[part 2 of 2: package /MICROSAR/Dcm_swc/ComponentTypes]
AUTOSAR XML (schema 4-3-0)
package /MICROSAR/Dcm_swc/ComponentTypes
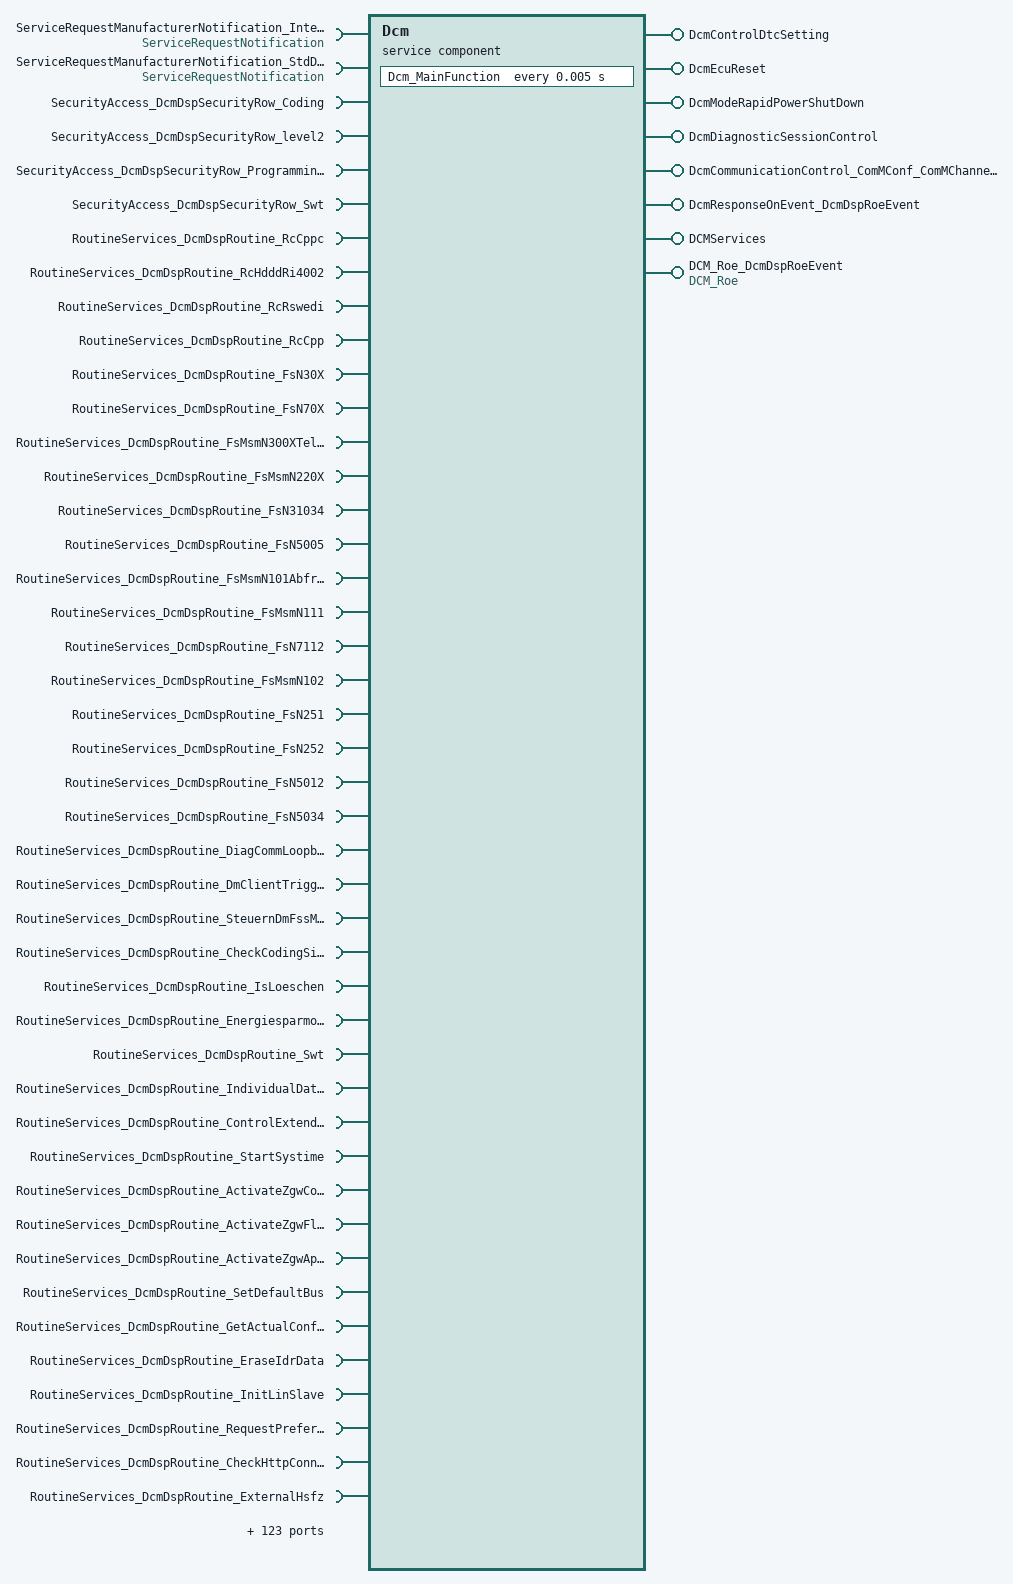
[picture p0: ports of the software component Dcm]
  service sw component type Dcm: category=SERVICE_COMPONENT
    8 x provide port:
      DcmControlDtcSetting: provided-interface=DcmControlDtcSetting
      DcmEcuReset: mode-switch-sender-com-spec{mode-group=DcmEcuReset, mode-switched-ack=timeout=0}, provided-interface=DcmEcuReset
      DcmModeRapidPowerShutDown: mode-switch-sender-com-spec{mode-group=DcmModeRapidPowerShutDown, mode-switched-ack=timeout=0}, provided-interface=DcmModeRapidPowerShutDown
      DcmDiagnosticSessionControl: provided-interface=DcmDiagnosticSessionControl
      DcmCommunicationControl_ComMConf_ComMChannel_A_FlexRay_5b5a9ac2: provided-interface=DcmCommunicationControl_ComMConf_ComMChannel_A_FlexRay_5b5a9ac2
      DcmResponseOnEvent_DcmDspRoeEvent: provided-interface=DcmResponseOnEvent_DcmDspRoeEvent
      DCMServices: provided-interface=DCMServices
      DCM_Roe_DcmDspRoeEvent: provided-interface=DCM_Roe
    169 x require port:
      ServiceRequestManufacturerNotification_IntegrationSample: required-interface=ServiceRequestNotification
      ServiceRequestManufacturerNotification_StdDiag: required-interface=ServiceRequestNotification
      SecurityAccess_DcmDspSecurityRow_Coding: required-interface=SecurityAccess_DcmDspSecurityRow_Coding
      SecurityAccess_DcmDspSecurityRow_level2: required-interface=SecurityAccess_DcmDspSecurityRow_level2
      SecurityAccess_DcmDspSecurityRow_Programming_HDD: required-interface=SecurityAccess_DcmDspSecurityRow_Programming_HDD
      SecurityAccess_DcmDspSecurityRow_Swt: required-interface=SecurityAccess_DcmDspSecurityRow_Swt
      RoutineServices_DcmDspRoutine_RcCppc: required-interface=RoutineServices_DcmDspRoutine_RcCppc
      RoutineServices_DcmDspRoutine_RcHdddRi4002: required-interface=RoutineServices_DcmDspRoutine_RcHdddRi4002
      RoutineServices_DcmDspRoutine_RcRswedi: required-interface=RoutineServices_DcmDspRoutine_RcRswedi
      RoutineServices_DcmDspRoutine_RcCpp: required-interface=RoutineServices_DcmDspRoutine_RcCpp
      RoutineServices_DcmDspRoutine_FsN30X: required-interface=RoutineServices_DcmDspRoutine_FsN30X
      RoutineServices_DcmDspRoutine_FsN70X: required-interface=RoutineServices_DcmDspRoutine_FsN70X
      RoutineServices_DcmDspRoutine_FsMsmN300XTeleservice: required-interface=RoutineServices_DcmDspRoutine_FsMsmN300XTeleservice
      RoutineServices_DcmDspRoutine_FsMsmN220X: required-interface=RoutineServices_DcmDspRoutine_FsMsmN220X
      RoutineServices_DcmDspRoutine_FsN31034: required-interface=RoutineServices_DcmDspRoutine_FsN31034
      RoutineServices_DcmDspRoutine_FsN5005: required-interface=RoutineServices_DcmDspRoutine_FsN5005
      RoutineServices_DcmDspRoutine_FsMsmN101AbfrageFzgsec: required-interface=RoutineServices_DcmDspRoutine_FsMsmN101AbfrageFzgsec
      RoutineServices_DcmDspRoutine_FsMsmN111: required-interface=RoutineServices_DcmDspRoutine_FsMsmN111
      RoutineServices_DcmDspRoutine_FsN7112: required-interface=RoutineServices_DcmDspRoutine_FsN7112
      RoutineServices_DcmDspRoutine_FsMsmN102: required-interface=RoutineServices_DcmDspRoutine_FsMsmN102
      RoutineServices_DcmDspRoutine_FsN251: required-interface=RoutineServices_DcmDspRoutine_FsN251
      RoutineServices_DcmDspRoutine_FsN252: required-interface=RoutineServices_DcmDspRoutine_FsN252
      RoutineServices_DcmDspRoutine_FsN5012: required-interface=RoutineServices_DcmDspRoutine_FsN5012
      RoutineServices_DcmDspRoutine_FsN5034: required-interface=RoutineServices_DcmDspRoutine_FsN5034
      RoutineServices_DcmDspRoutine_DiagCommLoopback: required-interface=RoutineServices_DcmDspRoutine_DiagCommLoopback
      RoutineServices_DcmDspRoutine_DmClientTriggerDtcEntry: required-interface=RoutineServices_DcmDspRoutine_DmClientTriggerDtcEntry
      RoutineServices_DcmDspRoutine_SteuernDmFssMaster: required-interface=RoutineServices_DcmDspRoutine_SteuernDmFssMaster
      RoutineServices_DcmDspRoutine_CheckCodingSignature: required-interface=RoutineServices_DcmDspRoutine_CheckCodingSignature
      RoutineServices_DcmDspRoutine_IsLoeschen: required-interface=RoutineServices_DcmDspRoutine_IsLoeschen
      RoutineServices_DcmDspRoutine_Energiesparmode: required-interface=RoutineServices_DcmDspRoutine_Energiesparmode
      RoutineServices_DcmDspRoutine_Swt: required-interface=RoutineServices_DcmDspRoutine_Swt
      RoutineServices_DcmDspRoutine_IndividualDatenRettung: required-interface=RoutineServices_DcmDspRoutine_IndividualDatenRettung
      RoutineServices_DcmDspRoutine_ControlExtendedEnergySavingState: required-interface=RoutineServices_DcmDspRoutine_ControlExtendedEnergySavingState
      RoutineServices_DcmDspRoutine_StartSystime: required-interface=RoutineServices_DcmDspRoutine_StartSystime
      RoutineServices_DcmDspRoutine_ActivateZgwCodingmode: required-interface=RoutineServices_DcmDspRoutine_ActivateZgwCodingmode
      RoutineServices_DcmDspRoutine_ActivateZgwFlashmode: required-interface=RoutineServices_DcmDspRoutine_ActivateZgwFlashmode
      RoutineServices_DcmDspRoutine_ActivateZgwApplicationmode: required-interface=RoutineServices_DcmDspRoutine_ActivateZgwApplicationmode
      RoutineServices_DcmDspRoutine_SetDefaultBus: required-interface=RoutineServices_DcmDspRoutine_SetDefaultBus
      RoutineServices_DcmDspRoutine_GetActualConfig: required-interface=RoutineServices_DcmDspRoutine_GetActualConfig
      RoutineServices_DcmDspRoutine_EraseIdrData: required-interface=RoutineServices_DcmDspRoutine_EraseIdrData
      RoutineServices_DcmDspRoutine_InitLinSlave: required-interface=RoutineServices_DcmDspRoutine_InitLinSlave
      RoutineServices_DcmDspRoutine_RequestPreferredProtocol: required-interface=RoutineServices_DcmDspRoutine_RequestPreferredProtocol
      RoutineServices_DcmDspRoutine_CheckHttpConnection: required-interface=RoutineServices_DcmDspRoutine_CheckHttpConnection
      RoutineServices_DcmDspRoutine_ExternalHsfz: required-interface=RoutineServices_DcmDspRoutine_ExternalHsfz
      RoutineServices_DcmDspRoutine_ResetAktivierungsleitung: required-interface=RoutineServices_DcmDspRoutine_ResetAktivierungsleitung
      RoutineServices_DcmDspRoutine_EthReadPhyRegister: required-interface=RoutineServices_DcmDspRoutine_EthReadPhyRegister
      RoutineServices_DcmDspRoutine_EthArlTable: required-interface=RoutineServices_DcmDspRoutine_EthArlTable
      RoutineServices_DcmDspRoutine_EthArpTable: required-interface=RoutineServices_DcmDspRoutine_EthArpTable
      RoutineServices_DcmDspRoutine_EthPhySwitchEngineReset: required-interface=RoutineServices_DcmDspRoutine_EthPhySwitchEngineReset
      RoutineServices_DcmDspRoutine_EthIpConfiguration: required-interface=RoutineServices_DcmDspRoutine_EthIpConfiguration
      RoutineServices_DcmDspRoutine_EthPhyIdentifier: required-interface=RoutineServices_DcmDspRoutine_EthPhyIdentifier
      RoutineServices_DcmDspRoutine_EthGetPortTxRxStats: required-interface=RoutineServices_DcmDspRoutine_EthGetPortTxRxStats
      RoutineServices_DcmDspRoutine_EthResetPortTxRxStats: required-interface=RoutineServices_DcmDspRoutine_EthResetPortTxRxStats
      RoutineServices_DcmDspRoutine_EthEnableTestMode: required-interface=RoutineServices_DcmDspRoutine_EthEnableTestMode
      RoutineServices_DcmDspRoutine_EthWritePhyRegister: required-interface=RoutineServices_DcmDspRoutine_EthWritePhyRegister
      RoutineServices_DcmDspRoutine_EthExtendedArlTable: required-interface=RoutineServices_DcmDspRoutine_EthExtendedArlTable
      RoutineServices_DcmDspRoutine_EthGetDhcpStatus: required-interface=RoutineServices_DcmDspRoutine_EthGetDhcpStatus
      RoutineServices_DcmDspRoutine_EthGetEthernetSwitches: required-interface=RoutineServices_DcmDspRoutine_EthGetEthernetSwitches
      RoutineServices_DcmDspRoutine_EthGetSwitchVlanConfiguration: required-interface=RoutineServices_DcmDspRoutine_EthGetSwitchVlanConfiguration
      RoutineServices_DcmDspRoutine_FehlerspeicherEndeWerksablauf: required-interface=RoutineServices_DcmDspRoutine_FehlerspeicherEndeWerksablauf
      RoutineServices_DcmDspRoutine_AblageSystemkontext: required-interface=RoutineServices_DcmDspRoutine_AblageSystemkontext
      RoutineServices_DcmDspRoutine_InitLinBus: required-interface=RoutineServices_DcmDspRoutine_InitLinBus
      RoutineServices_DcmDspRoutine_RamDatenSchreiben: required-interface=RoutineServices_DcmDspRoutine_RamDatenSchreiben
      RoutineServices_DcmDspRoutine_RcPad: required-interface=RoutineServices_DcmDspRoutine_RcPad
      DataServices_DcmDspData_SvkBackup39: required-interface=DataServices_DcmDspData_SvkBackup39
      DataServices_DcmDspData_SvkBackup38: required-interface=DataServices_DcmDspData_SvkBackup38
      DataServices_DcmDspData_SvkBackup37: required-interface=DataServices_DcmDspData_SvkBackup37
      DataServices_DcmDspData_SvkBackup36: required-interface=DataServices_DcmDspData_SvkBackup36
      DataServices_DcmDspData_SvkBackup35: required-interface=DataServices_DcmDspData_SvkBackup35
      DataServices_DcmDspData_SvkBackup34: required-interface=DataServices_DcmDspData_SvkBackup34
      DataServices_DcmDspData_SvkBackup33: required-interface=DataServices_DcmDspData_SvkBackup33
      DataServices_DcmDspData_SvkBackup32: required-interface=DataServices_DcmDspData_SvkBackup32
      DataServices_DcmDspData_SvkBackup31: required-interface=DataServices_DcmDspData_SvkBackup31
      DataServices_DcmDspData_SvkBackup30: required-interface=DataServices_DcmDspData_SvkBackup30
      DataServices_DcmDspData_EthGetNumberOfPorts: required-interface=DataServices_DcmDspData_EthGetNumberOfPorts
      DataServices_DcmDspData_SvkBackup28: required-interface=DataServices_DcmDspData_SvkBackup28
      DataServices_DcmDspData_SvkBackup27: required-interface=DataServices_DcmDspData_SvkBackup27
      DataServices_DcmDspData_SvkBackup26: required-interface=DataServices_DcmDspData_SvkBackup26
      DataServices_DcmDspData_SvkBackup25: required-interface=DataServices_DcmDspData_SvkBackup25
      DataServices_DcmDspData_SvkBackup24: required-interface=DataServices_DcmDspData_SvkBackup24
      DataServices_DcmDspData_SvkBackup23: required-interface=DataServices_DcmDspData_SvkBackup23
      DataServices_DcmDspData_SvkBackup22: required-interface=DataServices_DcmDspData_SvkBackup22
      DataServices_DcmDspData_SvkBackup21: required-interface=DataServices_DcmDspData_SvkBackup21
      DataServices_DcmDspData_SvkBackup20: required-interface=DataServices_DcmDspData_SvkBackup20
      DataServices_DcmDspData_SvkBackup29: required-interface=DataServices_DcmDspData_SvkBackup29
      DataServices_DcmDspData_ListManipulationSecurityArtifact: required-interface=DataServices_DcmDspData_ListManipulationSecurityArtifact
      DataServices_DcmDspData_SvkBackup17: required-interface=DataServices_DcmDspData_SvkBackup17
      DataServices_DcmDspData_SvkBackup16: required-interface=DataServices_DcmDspData_SvkBackup16
      DataServices_DcmDspData_SvkBackup15: required-interface=DataServices_DcmDspData_SvkBackup15
      DataServices_DcmDspData_SvkBackup14: required-interface=DataServices_DcmDspData_SvkBackup14
      DataServices_DcmDspData_SvkBackup13: required-interface=DataServices_DcmDspData_SvkBackup13
      DataServices_DcmDspData_SvkBackup12: required-interface=DataServices_DcmDspData_SvkBackup12
      DataServices_DcmDspData_SvkBackup11: required-interface=DataServices_DcmDspData_SvkBackup11
      DataServices_DcmDspData_SvkBackup10: required-interface=DataServices_DcmDspData_SvkBackup10
      DataServices_DcmDspData_SvkBackup19: required-interface=DataServices_DcmDspData_SvkBackup19
      DataServices_DcmDspData_SvkBackup18: required-interface=DataServices_DcmDspData_SvkBackup18
      DataServices_DcmDspData_SvkBackup06: required-interface=DataServices_DcmDspData_SvkBackup06
      DataServices_DcmDspData_SvkBackup05: required-interface=DataServices_DcmDspData_SvkBackup05
      DataServices_DcmDspData_SvkBackup04: required-interface=DataServices_DcmDspData_SvkBackup04
      DataServices_DcmDspData_SvkBackup03: required-interface=DataServices_DcmDspData_SvkBackup03
      DataServices_DcmDspData_SvkBackup02: required-interface=DataServices_DcmDspData_SvkBackup02
      DataServices_DcmDspData_SvkBackup01: required-interface=DataServices_DcmDspData_SvkBackup01
      DataServices_DcmDspData_StatusSystime: required-interface=DataServices_DcmDspData_StatusSystime
      DataServices_DcmDspData_SvkBackup09: required-interface=DataServices_DcmDspData_SvkBackup09
      DataServices_DcmDspData_SvkBackup08: required-interface=DataServices_DcmDspData_SvkBackup08
      DataServices_DcmDspData_SvkBackup07: required-interface=DataServices_DcmDspData_SvkBackup07
      DataServices_DcmDspData_HddDownloadTimeToCompletion: required-interface=DataServices_DcmDspData_HddDownloadTimeToCompletion
      DataServices_DcmDspData_StatusDmFssMaster: required-interface=DataServices_DcmDspData_StatusDmFssMaster
      DataServices_DcmDspData_HddDownloadStatus: required-interface=DataServices_DcmDspData_HddDownloadStatus
      DataServices_DcmDspData_SvkAktuell: required-interface=DataServices_DcmDspData_SvkAktuell
      DataServices_DcmDspData_Readhwmodificationindex: required-interface=DataServices_DcmDspData_Readhwmodificationindex
      DataServices_DcmDspData_SensorenAnzahlLesen: required-interface=DataServices_DcmDspData_SensorenAnzahlLesen
      DataServices_DcmDspData_IndivDataTable: required-interface=DataServices_DcmDspData_IndivDataTable
      DataServices_DcmDspData_DmDtcAktiveMeldung: required-interface=DataServices_DcmDspData_DmDtcAktiveMeldung
      DataServices_DcmDspData_SwfkDeleteSupported: required-interface=DataServices_DcmDspData_SwfkDeleteSupported
      DataServices_DcmDspData_FlashTimingParameter: required-interface=DataServices_DcmDspData_FlashTimingParameter
      DataServices_DcmDspData_ListManipulationApplicationData: required-interface=DataServices_DcmDspData_ListManipulationApplicationData
      DataServices_DcmDspData_Vin: required-interface=DataServices_DcmDspData_Vin
      DataServices_DcmDspData_EnergySavingState: required-interface=DataServices_DcmDspData_EnergySavingState
      DataServices_DcmDspData_ReadActiveSessionState: required-interface=DataServices_DcmDspData_ReadActiveSessionState
      DataServices_DcmDspData_EthPhyLinkState: required-interface=DataServices_DcmDspData_EthPhyLinkState
      DataServices_DcmDspData_EthSignalQuality: required-interface=DataServices_DcmDspData_EthSignalQuality
      DataServices_DcmDspData_ListManipulationSw: required-interface=DataServices_DcmDspData_ListManipulationSw
      DataServices_DcmDspData_Herstelldatum: required-interface=DataServices_DcmDspData_Herstelldatum
      DataServices_DcmDspData_Sekundaererfehlerspeicher: required-interface=DataServices_DcmDspData_Sekundaererfehlerspeicher
      DataServices_DcmDspData_SystemSupplierIdentifier: required-interface=DataServices_DcmDspData_SystemSupplierIdentifier
      DataServices_DcmDspData_MileKmEeprom: required-interface=DataServices_DcmDspData_MileKmEeprom
      DataServices_DcmDspData_ListManipulationGeneral: required-interface=DataServices_DcmDspData_ListManipulationGeneral
      DataServices_DcmDspData_SvkWerk: required-interface=DataServices_DcmDspData_SvkWerk
      DataServices_DcmDspData_ProgrammingCounterMaxValue: required-interface=DataServices_DcmDspData_ProgrammingCounterMaxValue
      DataServices_DcmDspData_EcuSerialNumber: required-interface=DataServices_DcmDspData_EcuSerialNumber
      DataServices_DcmDspData_SgbdIdx: required-interface=DataServices_DcmDspData_SgbdIdx
      DataServices_DcmDspData_ZgwZertifikat: required-interface=DataServices_DcmDspData_ZgwZertifikat
      DataServices_DcmDspData_ListManipulationSecureBoot: required-interface=DataServices_DcmDspData_ListManipulationSecureBoot
      DataServices_DcmDspData_DmIsDtcActiveResponse: required-interface=DataServices_DcmDspData_DmIsDtcActiveResponse
      DataServices_DcmDspData_ExtendedEnergySavingState: required-interface=DataServices_DcmDspData_ExtendedEnergySavingState
      DataServices_DcmDspData_SvkBackup61: required-interface=DataServices_DcmDspData_SvkBackup61
      DataServices_DcmDspData_PiaProfile0: required-interface=DataServices_DcmDspData_PiaProfile0
      DataServices_DcmDspData_SvkBackup60: required-interface=DataServices_DcmDspData_SvkBackup60
      DataServices_DcmDspData_PiaProfile1: required-interface=DataServices_DcmDspData_PiaProfile1
      DataServices_DcmDspData_PiaProfile2: required-interface=DataServices_DcmDspData_PiaProfile2
      DataServices_DcmDspData_SvkSysSupplier: required-interface=DataServices_DcmDspData_SvkSysSupplier
      DataServices_DcmDspData_PiaProfileA: required-interface=DataServices_DcmDspData_PiaProfileA
      DataServices_DcmDspData_SvkBackup59: required-interface=DataServices_DcmDspData_SvkBackup59
      DataServices_DcmDspData_SvkBackup58: required-interface=DataServices_DcmDspData_SvkBackup58
      DataServices_DcmDspData_SvkBackup57: required-interface=DataServices_DcmDspData_SvkBackup57
      DataServices_DcmDspData_SvkBackup56: required-interface=DataServices_DcmDspData_SvkBackup56
      DataServices_DcmDspData_SvkBackup55: required-interface=DataServices_DcmDspData_SvkBackup55
      DataServices_DcmDspData_SvkBackup54: required-interface=DataServices_DcmDspData_SvkBackup54
      DataServices_DcmDspData_SvkBackup53: required-interface=DataServices_DcmDspData_SvkBackup53
      DataServices_DcmDspData_SvkBackup52: required-interface=DataServices_DcmDspData_SvkBackup52
      DataServices_DcmDspData_SvkBackup51: required-interface=DataServices_DcmDspData_SvkBackup51
      DataServices_DcmDspData_SvkBackup50: required-interface=DataServices_DcmDspData_SvkBackup50
      DataServices_DcmDspData_ProgrammingCounter: required-interface=DataServices_DcmDspData_ProgrammingCounter
      DataServices_DcmDspData_Systemzeit: required-interface=DataServices_DcmDspData_Systemzeit
      DataServices_DcmDspData_SvkBackup49: required-interface=DataServices_DcmDspData_SvkBackup49
      DataServices_DcmDspData_SvkBackup48: required-interface=DataServices_DcmDspData_SvkBackup48
      DataServices_DcmDspData_SvkBackup47: required-interface=DataServices_DcmDspData_SvkBackup47
      DataServices_DcmDspData_SvkBackup46: required-interface=DataServices_DcmDspData_SvkBackup46
      DataServices_DcmDspData_SvkBackup45: required-interface=DataServices_DcmDspData_SvkBackup45
      DataServices_DcmDspData_SvkBackup44: required-interface=DataServices_DcmDspData_SvkBackup44
      DataServices_DcmDspData_SvkBackup43: required-interface=DataServices_DcmDspData_SvkBackup43
      DataServices_DcmDspData_SvkBackup42: required-interface=DataServices_DcmDspData_SvkBackup42
      DataServices_DcmDspData_SvkBackup41: required-interface=DataServices_DcmDspData_SvkBackup41
      DataServices_DcmDspData_SvkBackup40: required-interface=DataServices_DcmDspData_SvkBackup40
      DataServices_DIDRange_DcmDspDidRange_Coding: required-interface=DataServices_DIDRange_DcmDspDidRange_Coding
      DataServices_Data_DcmDspDid_SensorLesen_{1..3}: required-interface=DataServices_Data_DcmDspDid_SensorLesen_{1..3}
    behavior DcmInternalBehavior:
      data-type-mapping=DcmMappingSet
      handle-termination-and-restart=NO-SUPPORT
      included-data-type-set=data-type=[Dcm_ConfirmationStatusType, Dcm_OpStatusType, Dcm_DidSupportedType, Dcm_NegativeResponseCodeType, Dcm_ProtocolType, Dcm_RequestKindType, Dcm_SecLevelType, Dcm_SesCtrlType, Dcm_ControlDtcSettingType, Dcm_EcuResetType, Dcm_ModeRapidPowerShutDownType, Dcm_DiagnosticSessionControlType, Dcm_CommunicationModeType, Dcm_ResponseOnEventType]
      timing event Timer_Dcm_MainFunction: start-on-event=Dcm_MainFunction, period=0.005
      7 x operation invoked event:
        OpEventGetActiveProtocol_GetActiveProtocol_DCMServices: start-on-event=GetActiveProtocol, operation=DCMServices.GetActiveProtocol
        OpEventGetSesCtrlType_GetSesCtrlType_DCMServices: start-on-event=GetSesCtrlType, operation=DCMServices.GetSesCtrlType
        OpEventResetToDefaultSession_ResetToDefaultSession_DCMServices: start-on-event=ResetToDefaultSession, operation=DCMServices.ResetToDefaultSession
        OpEventGetSecurityLevel_GetSecurityLevel_DCMServices: start-on-event=GetSecurityLevel, operation=DCMServices.GetSecurityLevel
        OpEventSetActiveDiagnostic_SetActiveDiagnostic_DCMServices: start-on-event=SetActiveDiagnostic, operation=DCMServices.SetActiveDiagnostic
        OpEventGetRequestKind_GetRequestKind_DCMServices: start-on-event=GetRequestKind, operation=DCMServices.GetRequestKind
        OpEventTriggerOnEvent_TriggerOnEvent_DCM_Roe_DcmDspRoeEvent: start-on-event=TriggerOnEvent, operation=DCM_Roe_DcmDspRoeEvent.TriggerOnEvent
      port-api-options:
        enable-take-address=true, indirect-api=false, port=DcmControlDtcSetting
        enable-take-address=true, indirect-api=false, port=DcmEcuReset
        enable-take-address=true, indirect-api=false, port=DcmModeRapidPowerShutDown
        enable-take-address=true, indirect-api=false, port=DcmDiagnosticSessionControl
        enable-take-address=true, indirect-api=false, port=DcmCommunicationControl_ComMConf_ComMChannel_A_FlexRay_5b5a9ac2
        enable-take-address=true, indirect-api=false, port=DcmResponseOnEvent_DcmDspRoeEvent
        enable-take-address=true, indirect-api=false, port=DCMServices
        {enable-take-address=true, indirect-api=false, port-defined-argument-value{value=0, value-type=uint8}, port=DCM_Roe_DcmDspRoeEvent}
        enable-take-address=true, indirect-api=false, port=ServiceRequestManufacturerNotification_IntegrationSample
        enable-take-address=true, indirect-api=false, port=ServiceRequestManufacturerNotification_StdDiag
        enable-take-address=true, indirect-api=false, port=SecurityAccess_DcmDspSecurityRow_Coding
        enable-take-address=true, indirect-api=false, port=SecurityAccess_DcmDspSecurityRow_level2
        enable-take-address=true, indirect-api=false, port=SecurityAccess_DcmDspSecurityRow_Programming_HDD
        enable-take-address=true, indirect-api=false, port=SecurityAccess_DcmDspSecurityRow_Swt
        enable-take-address=true, indirect-api=false, port=RoutineServices_DcmDspRoutine_RcCppc
        enable-take-address=true, indirect-api=false, port=RoutineServices_DcmDspRoutine_RcHdddRi4002
        enable-take-address=true, indirect-api=false, port=RoutineServices_DcmDspRoutine_RcRswedi
        enable-take-address=true, indirect-api=false, port=RoutineServices_DcmDspRoutine_RcCpp
        enable-take-address=true, indirect-api=false, port=RoutineServices_DcmDspRoutine_FsN30X
        enable-take-address=true, indirect-api=false, port=RoutineServices_DcmDspRoutine_FsN70X
        enable-take-address=true, indirect-api=false, port=RoutineServices_DcmDspRoutine_FsMsmN300XTeleservice
        enable-take-address=true, indirect-api=false, port=RoutineServices_DcmDspRoutine_FsMsmN220X
        enable-take-address=true, indirect-api=false, port=RoutineServices_DcmDspRoutine_FsN31034
        enable-take-address=true, indirect-api=false, port=RoutineServices_DcmDspRoutine_FsN5005
        enable-take-address=true, indirect-api=false, port=RoutineServices_DcmDspRoutine_FsMsmN101AbfrageFzgsec
        enable-take-address=true, indirect-api=false, port=RoutineServices_DcmDspRoutine_FsMsmN111
        enable-take-address=true, indirect-api=false, port=RoutineServices_DcmDspRoutine_FsN7112
        enable-take-address=true, indirect-api=false, port=RoutineServices_DcmDspRoutine_FsMsmN102
        enable-take-address=true, indirect-api=false, port=RoutineServices_DcmDspRoutine_FsN251
        enable-take-address=true, indirect-api=false, port=RoutineServices_DcmDspRoutine_FsN252
        enable-take-address=true, indirect-api=false, port=RoutineServices_DcmDspRoutine_FsN5012
        enable-take-address=true, indirect-api=false, port=RoutineServices_DcmDspRoutine_FsN5034
        enable-take-address=true, indirect-api=false, port=RoutineServices_DcmDspRoutine_DiagCommLoopback
        enable-take-address=true, indirect-api=false, port=RoutineServices_DcmDspRoutine_DmClientTriggerDtcEntry
        enable-take-address=true, indirect-api=false, port=RoutineServices_DcmDspRoutine_SteuernDmFssMaster
        enable-take-address=true, indirect-api=false, port=RoutineServices_DcmDspRoutine_CheckCodingSignature
        enable-take-address=true, indirect-api=false, port=RoutineServices_DcmDspRoutine_IsLoeschen
        enable-take-address=true, indirect-api=false, port=RoutineServices_DcmDspRoutine_Energiesparmode
        enable-take-address=true, indirect-api=false, port=RoutineServices_DcmDspRoutine_Swt
        enable-take-address=true, indirect-api=false, port=RoutineServices_DcmDspRoutine_IndividualDatenRettung
        enable-take-address=true, indirect-api=false, port=RoutineServices_DcmDspRoutine_ControlExtendedEnergySavingState
        enable-take-address=true, indirect-api=false, port=RoutineServices_DcmDspRoutine_StartSystime
        enable-take-address=true, indirect-api=false, port=RoutineServices_DcmDspRoutine_ActivateZgwCodingmode
        enable-take-address=true, indirect-api=false, port=RoutineServices_DcmDspRoutine_ActivateZgwFlashmode
        enable-take-address=true, indirect-api=false, port=RoutineServices_DcmDspRoutine_ActivateZgwApplicationmode
        enable-take-address=true, indirect-api=false, port=RoutineServices_DcmDspRoutine_SetDefaultBus
        enable-take-address=true, indirect-api=false, port=RoutineServices_DcmDspRoutine_GetActualConfig
        enable-take-address=true, indirect-api=false, port=RoutineServices_DcmDspRoutine_EraseIdrData
        enable-take-address=true, indirect-api=false, port=RoutineServices_DcmDspRoutine_InitLinSlave
        enable-take-address=true, indirect-api=false, port=RoutineServices_DcmDspRoutine_RequestPreferredProtocol
        enable-take-address=true, indirect-api=false, port=RoutineServices_DcmDspRoutine_CheckHttpConnection
        enable-take-address=true, indirect-api=false, port=RoutineServices_DcmDspRoutine_ExternalHsfz
        enable-take-address=true, indirect-api=false, port=RoutineServices_DcmDspRoutine_ResetAktivierungsleitung
        enable-take-address=true, indirect-api=false, port=RoutineServices_DcmDspRoutine_EthReadPhyRegister
        enable-take-address=true, indirect-api=false, port=RoutineServices_DcmDspRoutine_EthArlTable
        enable-take-address=true, indirect-api=false, port=RoutineServices_DcmDspRoutine_EthArpTable
        enable-take-address=true, indirect-api=false, port=RoutineServices_DcmDspRoutine_EthPhySwitchEngineReset
        enable-take-address=true, indirect-api=false, port=RoutineServices_DcmDspRoutine_EthIpConfiguration
        enable-take-address=true, indirect-api=false, port=RoutineServices_DcmDspRoutine_EthPhyIdentifier
        enable-take-address=true, indirect-api=false, port=RoutineServices_DcmDspRoutine_EthGetPortTxRxStats
        enable-take-address=true, indirect-api=false, port=RoutineServices_DcmDspRoutine_EthResetPortTxRxStats
        enable-take-address=true, indirect-api=false, port=RoutineServices_DcmDspRoutine_EthEnableTestMode
        enable-take-address=true, indirect-api=false, port=RoutineServices_DcmDspRoutine_EthWritePhyRegister
        enable-take-address=true, indirect-api=false, port=RoutineServices_DcmDspRoutine_EthExtendedArlTable
        enable-take-address=true, indirect-api=false, port=RoutineServices_DcmDspRoutine_EthGetDhcpStatus
        enable-take-address=true, indirect-api=false, port=RoutineServices_DcmDspRoutine_EthGetEthernetSwitches
        enable-take-address=true, indirect-api=false, port=RoutineServices_DcmDspRoutine_EthGetSwitchVlanConfiguration
        enable-take-address=true, indirect-api=false, port=RoutineServices_DcmDspRoutine_FehlerspeicherEndeWerksablauf
        enable-take-address=true, indirect-api=false, port=RoutineServices_DcmDspRoutine_AblageSystemkontext
        enable-take-address=true, indirect-api=false, port=RoutineServices_DcmDspRoutine_InitLinBus
        enable-take-address=true, indirect-api=false, port=RoutineServices_DcmDspRoutine_RamDatenSchreiben
        enable-take-address=true, indirect-api=false, port=RoutineServices_DcmDspRoutine_RcPad
        enable-take-address=true, indirect-api=false, port=DataServices_DcmDspData_SvkBackup39
        enable-take-address=true, indirect-api=false, port=DataServices_DcmDspData_SvkBackup38
        enable-take-address=true, indirect-api=false, port=DataServices_DcmDspData_SvkBackup37
        enable-take-address=true, indirect-api=false, port=DataServices_DcmDspData_SvkBackup36
        enable-take-address=true, indirect-api=false, port=DataServices_DcmDspData_SvkBackup35
        enable-take-address=true, indirect-api=false, port=DataServices_DcmDspData_SvkBackup34
        enable-take-address=true, indirect-api=false, port=DataServices_DcmDspData_SvkBackup33
        enable-take-address=true, indirect-api=false, port=DataServices_DcmDspData_SvkBackup32
        enable-take-address=true, indirect-api=false, port=DataServices_DcmDspData_SvkBackup31
        enable-take-address=true, indirect-api=false, port=DataServices_DcmDspData_SvkBackup30
        enable-take-address=true, indirect-api=false, port=DataServices_DcmDspData_EthGetNumberOfPorts
        enable-take-address=true, indirect-api=false, port=DataServices_DcmDspData_SvkBackup28
        enable-take-address=true, indirect-api=false, port=DataServices_DcmDspData_SvkBackup27
        enable-take-address=true, indirect-api=false, port=DataServices_DcmDspData_SvkBackup26
        enable-take-address=true, indirect-api=false, port=DataServices_DcmDspData_SvkBackup25
        enable-take-address=true, indirect-api=false, port=DataServices_DcmDspData_SvkBackup24
        enable-take-address=true, indirect-api=false, port=DataServices_DcmDspData_SvkBackup23
        enable-take-address=true, indirect-api=false, port=DataServices_DcmDspData_SvkBackup22
        enable-take-address=true, indirect-api=false, port=DataServices_DcmDspData_SvkBackup21
        enable-take-address=true, indirect-api=false, port=DataServices_DcmDspData_SvkBackup20
        enable-take-address=true, indirect-api=false, port=DataServices_DcmDspData_SvkBackup29
        enable-take-address=true, indirect-api=false, port=DataServices_DcmDspData_ListManipulationSecurityArtifact
        enable-take-address=true, indirect-api=false, port=DataServices_DcmDspData_SvkBackup17
        enable-take-address=true, indirect-api=false, port=DataServices_DcmDspData_SvkBackup16
        enable-take-address=true, indirect-api=false, port=DataServices_DcmDspData_SvkBackup15
        enable-take-address=true, indirect-api=false, port=DataServices_DcmDspData_SvkBackup14
        enable-take-address=true, indirect-api=false, port=DataServices_DcmDspData_SvkBackup13
        enable-take-address=true, indirect-api=false, port=DataServices_DcmDspData_SvkBackup12
        enable-take-address=true, indirect-api=false, port=DataServices_DcmDspData_SvkBackup11
        enable-take-address=true, indirect-api=false, port=DataServices_DcmDspData_SvkBackup10
        enable-take-address=true, indirect-api=false, port=DataServices_DcmDspData_SvkBackup19
        enable-take-address=true, indirect-api=false, port=DataServices_DcmDspData_SvkBackup18
        enable-take-address=true, indirect-api=false, port=DataServices_DcmDspData_SvkBackup06
        enable-take-address=true, indirect-api=false, port=DataServices_DcmDspData_SvkBackup05
        enable-take-address=true, indirect-api=false, port=DataServices_DcmDspData_SvkBackup04
        enable-take-address=true, indirect-api=false, port=DataServices_DcmDspData_SvkBackup03
        enable-take-address=true, indirect-api=false, port=DataServices_DcmDspData_SvkBackup02
        enable-take-address=true, indirect-api=false, port=DataServices_DcmDspData_SvkBackup01
        enable-take-address=true, indirect-api=false, port=DataServices_DcmDspData_StatusSystime
        enable-take-address=true, indirect-api=false, port=DataServices_DcmDspData_SvkBackup09
        enable-take-address=true, indirect-api=false, port=DataServices_DcmDspData_SvkBackup08
        enable-take-address=true, indirect-api=false, port=DataServices_DcmDspData_SvkBackup07
        enable-take-address=true, indirect-api=false, port=DataServices_DcmDspData_HddDownloadTimeToCompletion
        enable-take-address=true, indirect-api=false, port=DataServices_DcmDspData_StatusDmFssMaster
        enable-take-address=true, indirect-api=false, port=DataServices_DcmDspData_HddDownloadStatus
        enable-take-address=true, indirect-api=false, port=DataServices_DcmDspData_SvkAktuell
        enable-take-address=true, indirect-api=false, port=DataServices_DcmDspData_Readhwmodificationindex
        enable-take-address=true, indirect-api=false, port=DataServices_DcmDspData_SensorenAnzahlLesen
        enable-take-address=true, indirect-api=false, port=DataServices_DcmDspData_IndivDataTable
        enable-take-address=true, indirect-api=false, port=DataServices_DcmDspData_DmDtcAktiveMeldung
        enable-take-address=true, indirect-api=false, port=DataServices_DcmDspData_SwfkDeleteSupported
        enable-take-address=true, indirect-api=false, port=DataServices_DcmDspData_FlashTimingParameter
        enable-take-address=true, indirect-api=false, port=DataServices_DcmDspData_ListManipulationApplicationData
        enable-take-address=true, indirect-api=false, port=DataServices_DcmDspData_Vin
        enable-take-address=true, indirect-api=false, port=DataServices_DcmDspData_EnergySavingState
        enable-take-address=true, indirect-api=false, port=DataServices_DcmDspData_ReadActiveSessionState
        enable-take-address=true, indirect-api=false, port=DataServices_DcmDspData_EthPhyLinkState
        enable-take-address=true, indirect-api=false, port=DataServices_DcmDspData_EthSignalQuality
        enable-take-address=true, indirect-api=false, port=DataServices_DcmDspData_ListManipulationSw
        enable-take-address=true, indirect-api=false, port=DataServices_DcmDspData_Herstelldatum
        enable-take-address=true, indirect-api=false, port=DataServices_DcmDspData_Sekundaererfehlerspeicher
        enable-take-address=true, indirect-api=false, port=DataServices_DcmDspData_SystemSupplierIdentifier
        enable-take-address=true, indirect-api=false, port=DataServices_DcmDspData_MileKmEeprom
        enable-take-address=true, indirect-api=false, port=DataServices_DcmDspData_ListManipulationGeneral
        enable-take-address=true, indirect-api=false, port=DataServices_DcmDspData_SvkWerk
        enable-take-address=true, indirect-api=false, port=DataServices_DcmDspData_ProgrammingCounterMaxValue
        enable-take-address=true, indirect-api=false, port=DataServices_DcmDspData_EcuSerialNumber
        enable-take-address=true, indirect-api=false, port=DataServices_DcmDspData_SgbdIdx
        enable-take-address=true, indirect-api=false, port=DataServices_DcmDspData_ZgwZertifikat
        enable-take-address=true, indirect-api=false, port=DataServices_DcmDspData_ListManipulationSecureBoot
        enable-take-address=true, indirect-api=false, port=DataServices_DcmDspData_DmIsDtcActiveResponse
        enable-take-address=true, indirect-api=false, port=DataServices_DcmDspData_ExtendedEnergySavingState
        enable-take-address=true, indirect-api=false, port=DataServices_DcmDspData_SvkBackup61
        enable-take-address=true, indirect-api=false, port=DataServices_DcmDspData_PiaProfile0
        enable-take-address=true, indirect-api=false, port=DataServices_DcmDspData_SvkBackup60
        enable-take-address=true, indirect-api=false, port=DataServices_DcmDspData_PiaProfile1
        enable-take-address=true, indirect-api=false, port=DataServices_DcmDspData_PiaProfile2
        enable-take-address=true, indirect-api=false, port=DataServices_DcmDspData_SvkSysSupplier
        enable-take-address=true, indirect-api=false, port=DataServices_DcmDspData_PiaProfileA
        enable-take-address=true, indirect-api=false, port=DataServices_DcmDspData_SvkBackup59
        enable-take-address=true, indirect-api=false, port=DataServices_DcmDspData_SvkBackup58
        enable-take-address=true, indirect-api=false, port=DataServices_DcmDspData_SvkBackup57
        enable-take-address=true, indirect-api=false, port=DataServices_DcmDspData_SvkBackup56
        enable-take-address=true, indirect-api=false, port=DataServices_DcmDspData_SvkBackup55
        enable-take-address=true, indirect-api=false, port=DataServices_DcmDspData_SvkBackup54
        enable-take-address=true, indirect-api=false, port=DataServices_DcmDspData_SvkBackup53
        enable-take-address=true, indirect-api=false, port=DataServices_DcmDspData_SvkBackup52
        enable-take-address=true, indirect-api=false, port=DataServices_DcmDspData_SvkBackup51
        enable-take-address=true, indirect-api=false, port=DataServices_DcmDspData_SvkBackup50
        enable-take-address=true, indirect-api=false, port=DataServices_DcmDspData_ProgrammingCounter
        enable-take-address=true, indirect-api=false, port=DataServices_DcmDspData_Systemzeit
        enable-take-address=true, indirect-api=false, port=DataServices_DcmDspData_SvkBackup49
        enable-take-address=true, indirect-api=false, port=DataServices_DcmDspData_SvkBackup48
        enable-take-address=true, indirect-api=false, port=DataServices_DcmDspData_SvkBackup47
        enable-take-address=true, indirect-api=false, port=DataServices_DcmDspData_SvkBackup46
        enable-take-address=true, indirect-api=false, port=DataServices_DcmDspData_SvkBackup45
        enable-take-address=true, indirect-api=false, port=DataServices_DcmDspData_SvkBackup44
        enable-take-address=true, indirect-api=false, port=DataServices_DcmDspData_SvkBackup43
        enable-take-address=true, indirect-api=false, port=DataServices_DcmDspData_SvkBackup42
        enable-take-address=true, indirect-api=false, port=DataServices_DcmDspData_SvkBackup41
        enable-take-address=true, indirect-api=false, port=DataServices_DcmDspData_SvkBackup40
        enable-take-address=true, indirect-api=false, port=DataServices_DIDRange_DcmDspDidRange_Coding
        enable-take-address=true, indirect-api=false, port=DataServices_Data_DcmDspDid_SensorLesen_{1..3}
      8 x runnable:
        Dcm_MainFunction
          6 x mode switch point:
            ModeSwitchPointDcm_MainFunction_DcmControlDtcSetting_DcmControlDtcSetting: mode-group=DcmControlDtcSetting.DcmControlDtcSetting
            ModeSwitchPointDcm_MainFunction_DcmEcuReset_DcmEcuReset: mode-group=DcmEcuReset.DcmEcuReset
            ModeSwitchPointDcm_MainFunction_DcmModeRapidPowerShutDown_DcmModeRapidPowerShutDown: mode-group=DcmModeRapidPowerShutDown.DcmModeRapidPowerShutDown
            ModeSwitchPointDcm_MainFunction_DcmDiagnosticSessionControl_DcmDiagnosticSessionControl: mode-group=DcmDiagnosticSessionControl.DcmDiagnosticSessionControl
            ModeSwitchPointDcm_MainFunction_DcmCommunicationControl_ComMConf_ComMChannel_A_FlexRay_5b5a9ac2_DcmCommunicationControl_aef52ce2: mode-group=DcmCommunicationControl_ComMConf_ComMChannel_A_FlexRay_5b5a9ac2.DcmCommunicationControl_ComMConf_ComMChannel_A_FlexRay_5b5a9ac2
            ModeSwitchPointDcm_MainFunction_DcmResponseOnEvent_DcmDspRoeEvent_DcmResponseOnEvent_DcmDspRoeEvent: mode-group=DcmResponseOnEvent_DcmDspRoeEvent.DcmResponseOnEvent_DcmDspRoeEvent
          292 x sync call, all with timeout=0:
            OpServerCallDcm_MainFunction_Indication_ServiceRequestManufacturerNotification_IntegrationSample: operation=ServiceRequestManufacturerNotification_IntegrationSample.Indication
            OpServerCallDcm_MainFunction_Confirmation_ServiceRequestManufacturerNotification_IntegrationSample: operation=ServiceRequestManufacturerNotification_IntegrationSample.Confirmation
            OpServerCallDcm_MainFunction_Indication_ServiceRequestManufacturerNotification_StdDiag: operation=ServiceRequestManufacturerNotification_StdDiag.Indication
            OpServerCallDcm_MainFunction_Confirmation_ServiceRequestManufacturerNotification_StdDiag: operation=ServiceRequestManufacturerNotification_StdDiag.Confirmation
            OpServerCallDcm_MainFunction_GetSeed_SecurityAccess_DcmDspSecurityRow_Coding: operation=SecurityAccess_DcmDspSecurityRow_Coding.GetSeed
            OpServerCallDcm_MainFunction_CompareKey_SecurityAccess_DcmDspSecurityRow_Coding: operation=SecurityAccess_DcmDspSecurityRow_Coding.CompareKey
            OpServerCallDcm_MainFunction_GetSeed_SecurityAccess_DcmDspSecurityRow_level2: operation=SecurityAccess_DcmDspSecurityRow_level2.GetSeed
            OpServerCallDcm_MainFunction_CompareKey_SecurityAccess_DcmDspSecurityRow_level2: operation=SecurityAccess_DcmDspSecurityRow_level2.CompareKey
            OpServerCallDcm_MainFunction_GetSeed_SecurityAccess_DcmDspSecurityRow_Programming_HDD: operation=SecurityAccess_DcmDspSecurityRow_Programming_HDD.GetSeed
            OpServerCallDcm_MainFunction_CompareKey_SecurityAccess_DcmDspSecurityRow_Programming_HDD: operation=SecurityAccess_DcmDspSecurityRow_Programming_HDD.CompareKey
            OpServerCallDcm_MainFunction_GetSeed_SecurityAccess_DcmDspSecurityRow_Swt: operation=SecurityAccess_DcmDspSecurityRow_Swt.GetSeed
            OpServerCallDcm_MainFunction_CompareKey_SecurityAccess_DcmDspSecurityRow_Swt: operation=SecurityAccess_DcmDspSecurityRow_Swt.CompareKey
            OpServerCallDcm_MainFunction_Start_RoutineServices_DcmDspRoutine_RcCppc: operation=RoutineServices_DcmDspRoutine_RcCppc.Start
            OpServerCallDcm_MainFunction_Start_RoutineServices_DcmDspRoutine_RcHdddRi4002: operation=RoutineServices_DcmDspRoutine_RcHdddRi4002.Start
            OpServerCallDcm_MainFunction_Start_RoutineServices_DcmDspRoutine_RcRswedi: operation=RoutineServices_DcmDspRoutine_RcRswedi.Start
            OpServerCallDcm_MainFunction_Start_RoutineServices_DcmDspRoutine_RcCpp: operation=RoutineServices_DcmDspRoutine_RcCpp.Start
            OpServerCallDcm_MainFunction_Start_RoutineServices_DcmDspRoutine_FsN30X: operation=RoutineServices_DcmDspRoutine_FsN30X.Start
            OpServerCallDcm_MainFunction_RequestResults_RoutineServices_DcmDspRoutine_FsN30X: operation=RoutineServices_DcmDspRoutine_FsN30X.RequestResults
            OpServerCallDcm_MainFunction_Start_RoutineServices_DcmDspRoutine_FsN70X: operation=RoutineServices_DcmDspRoutine_FsN70X.Start
            OpServerCallDcm_MainFunction_RequestResults_RoutineServices_DcmDspRoutine_FsN70X: operation=RoutineServices_DcmDspRoutine_FsN70X.RequestResults
            OpServerCallDcm_MainFunction_Start_RoutineServices_DcmDspRoutine_FsMsmN300XTeleservice: operation=RoutineServices_DcmDspRoutine_FsMsmN300XTeleservice.Start
            OpServerCallDcm_MainFunction_RequestResults_RoutineServices_DcmDspRoutine_FsMsmN300XTeleservice: operation=RoutineServices_DcmDspRoutine_FsMsmN300XTeleservice.RequestResults
            OpServerCallDcm_MainFunction_Start_RoutineServices_DcmDspRoutine_FsMsmN220X: operation=RoutineServices_DcmDspRoutine_FsMsmN220X.Start
            OpServerCallDcm_MainFunction_Start_RoutineServices_DcmDspRoutine_FsN31034: operation=RoutineServices_DcmDspRoutine_FsN31034.Start
            OpServerCallDcm_MainFunction_Start_RoutineServices_DcmDspRoutine_FsN5005: operation=RoutineServices_DcmDspRoutine_FsN5005.Start
            OpServerCallDcm_MainFunction_RequestResults_RoutineServices_DcmDspRoutine_FsN5005: operation=RoutineServices_DcmDspRoutine_FsN5005.RequestResults
            OpServerCallDcm_MainFunction_Start_RoutineServices_DcmDspRoutine_FsMsmN101AbfrageFzgsec: operation=RoutineServices_DcmDspRoutine_FsMsmN101AbfrageFzgsec.Start
            OpServerCallDcm_MainFunction_Start_RoutineServices_DcmDspRoutine_FsMsmN111: operation=RoutineServices_DcmDspRoutine_FsMsmN111.Start
            OpServerCallDcm_MainFunction_Start_RoutineServices_DcmDspRoutine_FsN7112: operation=RoutineServices_DcmDspRoutine_FsN7112.Start
            OpServerCallDcm_MainFunction_RequestResults_RoutineServices_DcmDspRoutine_FsN7112: operation=RoutineServices_DcmDspRoutine_FsN7112.RequestResults
            OpServerCallDcm_MainFunction_Start_RoutineServices_DcmDspRoutine_FsMsmN102: operation=RoutineServices_DcmDspRoutine_FsMsmN102.Start
            OpServerCallDcm_MainFunction_Start_RoutineServices_DcmDspRoutine_FsN251: operation=RoutineServices_DcmDspRoutine_FsN251.Start
            OpServerCallDcm_MainFunction_Start_RoutineServices_DcmDspRoutine_FsN252: operation=RoutineServices_DcmDspRoutine_FsN252.Start
            OpServerCallDcm_MainFunction_Start_RoutineServices_DcmDspRoutine_FsN5012: operation=RoutineServices_DcmDspRoutine_FsN5012.Start
            OpServerCallDcm_MainFunction_RequestResults_RoutineServices_DcmDspRoutine_FsN5012: operation=RoutineServices_DcmDspRoutine_FsN5012.RequestResults
            OpServerCallDcm_MainFunction_Start_RoutineServices_DcmDspRoutine_FsN5034: operation=RoutineServices_DcmDspRoutine_FsN5034.Start
            OpServerCallDcm_MainFunction_RequestResults_RoutineServices_DcmDspRoutine_FsN5034: operation=RoutineServices_DcmDspRoutine_FsN5034.RequestResults
            OpServerCallDcm_MainFunction_Start_RoutineServices_DcmDspRoutine_DiagCommLoopback: operation=RoutineServices_DcmDspRoutine_DiagCommLoopback.Start
            OpServerCallDcm_MainFunction_Start_RoutineServices_DcmDspRoutine_DmClientTriggerDtcEntry: operation=RoutineServices_DcmDspRoutine_DmClientTriggerDtcEntry.Start
            OpServerCallDcm_MainFunction_Start_RoutineServices_DcmDspRoutine_SteuernDmFssMaster: operation=RoutineServices_DcmDspRoutine_SteuernDmFssMaster.Start
            OpServerCallDcm_MainFunction_Stop_RoutineServices_DcmDspRoutine_SteuernDmFssMaster: operation=RoutineServices_DcmDspRoutine_SteuernDmFssMaster.Stop
            OpServerCallDcm_MainFunction_Start_RoutineServices_DcmDspRoutine_CheckCodingSignature: operation=RoutineServices_DcmDspRoutine_CheckCodingSignature.Start
            OpServerCallDcm_MainFunction_Start_RoutineServices_DcmDspRoutine_IsLoeschen: operation=RoutineServices_DcmDspRoutine_IsLoeschen.Start
            OpServerCallDcm_MainFunction_Start_RoutineServices_DcmDspRoutine_Energiesparmode: operation=RoutineServices_DcmDspRoutine_Energiesparmode.Start
            OpServerCallDcm_MainFunction_Start_RoutineServices_DcmDspRoutine_Swt: operation=RoutineServices_DcmDspRoutine_Swt.Start
            OpServerCallDcm_MainFunction_Start_RoutineServices_DcmDspRoutine_IndividualDatenRettung: operation=RoutineServices_DcmDspRoutine_IndividualDatenRettung.Start
            OpServerCallDcm_MainFunction_Start_RoutineServices_DcmDspRoutine_ControlExtendedEnergySavingState: operation=RoutineServices_DcmDspRoutine_ControlExtendedEnergySavingState.Start
            OpServerCallDcm_MainFunction_Start_RoutineServices_DcmDspRoutine_StartSystime: operation=RoutineServices_DcmDspRoutine_StartSystime.Start
            OpServerCallDcm_MainFunction_Start_RoutineServices_DcmDspRoutine_ActivateZgwCodingmode: operation=RoutineServices_DcmDspRoutine_ActivateZgwCodingmode.Start
            OpServerCallDcm_MainFunction_Start_RoutineServices_DcmDspRoutine_ActivateZgwFlashmode: operation=RoutineServices_DcmDspRoutine_ActivateZgwFlashmode.Start
            OpServerCallDcm_MainFunction_Start_RoutineServices_DcmDspRoutine_ActivateZgwApplicationmode: operation=RoutineServices_DcmDspRoutine_ActivateZgwApplicationmode.Start
            OpServerCallDcm_MainFunction_Start_RoutineServices_DcmDspRoutine_SetDefaultBus: operation=RoutineServices_DcmDspRoutine_SetDefaultBus.Start
            OpServerCallDcm_MainFunction_Start_RoutineServices_DcmDspRoutine_GetActualConfig: operation=RoutineServices_DcmDspRoutine_GetActualConfig.Start
            OpServerCallDcm_MainFunction_Start_RoutineServices_DcmDspRoutine_EraseIdrData: operation=RoutineServices_DcmDspRoutine_EraseIdrData.Start
            OpServerCallDcm_MainFunction_Start_RoutineServices_DcmDspRoutine_InitLinSlave: operation=RoutineServices_DcmDspRoutine_InitLinSlave.Start
            OpServerCallDcm_MainFunction_Start_RoutineServices_DcmDspRoutine_RequestPreferredProtocol: operation=RoutineServices_DcmDspRoutine_RequestPreferredProtocol.Start
            OpServerCallDcm_MainFunction_Start_RoutineServices_DcmDspRoutine_CheckHttpConnection: operation=RoutineServices_DcmDspRoutine_CheckHttpConnection.Start
            OpServerCallDcm_MainFunction_Start_RoutineServices_DcmDspRoutine_ExternalHsfz: operation=RoutineServices_DcmDspRoutine_ExternalHsfz.Start
            OpServerCallDcm_MainFunction_Start_RoutineServices_DcmDspRoutine_ResetAktivierungsleitung: operation=RoutineServices_DcmDspRoutine_ResetAktivierungsleitung.Start
            OpServerCallDcm_MainFunction_Start_RoutineServices_DcmDspRoutine_EthReadPhyRegister: operation=RoutineServices_DcmDspRoutine_EthReadPhyRegister.Start
            OpServerCallDcm_MainFunction_Start_RoutineServices_DcmDspRoutine_EthArlTable: operation=RoutineServices_DcmDspRoutine_EthArlTable.Start
            OpServerCallDcm_MainFunction_Start_RoutineServices_DcmDspRoutine_EthArpTable: operation=RoutineServices_DcmDspRoutine_EthArpTable.Start
            OpServerCallDcm_MainFunction_Start_RoutineServices_DcmDspRoutine_EthPhySwitchEngineReset: operation=RoutineServices_DcmDspRoutine_EthPhySwitchEngineReset.Start
            OpServerCallDcm_MainFunction_Start_RoutineServices_DcmDspRoutine_EthIpConfiguration: operation=RoutineServices_DcmDspRoutine_EthIpConfiguration.Start
            OpServerCallDcm_MainFunction_Start_RoutineServices_DcmDspRoutine_EthPhyIdentifier: operation=RoutineServices_DcmDspRoutine_EthPhyIdentifier.Start
            OpServerCallDcm_MainFunction_Start_RoutineServices_DcmDspRoutine_EthGetPortTxRxStats: operation=RoutineServices_DcmDspRoutine_EthGetPortTxRxStats.Start
            OpServerCallDcm_MainFunction_Start_RoutineServices_DcmDspRoutine_EthResetPortTxRxStats: operation=RoutineServices_DcmDspRoutine_EthResetPortTxRxStats.Start
            OpServerCallDcm_MainFunction_Start_RoutineServices_DcmDspRoutine_EthEnableTestMode: operation=RoutineServices_DcmDspRoutine_EthEnableTestMode.Start
            OpServerCallDcm_MainFunction_Start_RoutineServices_DcmDspRoutine_EthWritePhyRegister: operation=RoutineServices_DcmDspRoutine_EthWritePhyRegister.Start
            OpServerCallDcm_MainFunction_Start_RoutineServices_DcmDspRoutine_EthExtendedArlTable: operation=RoutineServices_DcmDspRoutine_EthExtendedArlTable.Start
            OpServerCallDcm_MainFunction_Start_RoutineServices_DcmDspRoutine_EthGetDhcpStatus: operation=RoutineServices_DcmDspRoutine_EthGetDhcpStatus.Start
            OpServerCallDcm_MainFunction_Start_RoutineServices_DcmDspRoutine_EthGetEthernetSwitches: operation=RoutineServices_DcmDspRoutine_EthGetEthernetSwitches.Start
            OpServerCallDcm_MainFunction_Start_RoutineServices_DcmDspRoutine_EthGetSwitchVlanConfiguration: operation=RoutineServices_DcmDspRoutine_EthGetSwitchVlanConfiguration.Start
            OpServerCallDcm_MainFunction_Start_RoutineServices_DcmDspRoutine_FehlerspeicherEndeWerksablauf: operation=RoutineServices_DcmDspRoutine_FehlerspeicherEndeWerksablauf.Start
            OpServerCallDcm_MainFunction_RequestResults_RoutineServices_DcmDspRoutine_FehlerspeicherEndeWerksablauf: operation=RoutineServices_DcmDspRoutine_FehlerspeicherEndeWerksablauf.RequestResults
            OpServerCallDcm_MainFunction_Start_RoutineServices_DcmDspRoutine_AblageSystemkontext: operation=RoutineServices_DcmDspRoutine_AblageSystemkontext.Start
            OpServerCallDcm_MainFunction_Start_RoutineServices_DcmDspRoutine_InitLinBus: operation=RoutineServices_DcmDspRoutine_InitLinBus.Start
            OpServerCallDcm_MainFunction_Start_RoutineServices_DcmDspRoutine_RamDatenSchreiben: operation=RoutineServices_DcmDspRoutine_RamDatenSchreiben.Start
            OpServerCallDcm_MainFunction_RequestResults_RoutineServices_DcmDspRoutine_RamDatenSchreiben: operation=RoutineServices_DcmDspRoutine_RamDatenSchreiben.RequestResults
            OpServerCallDcm_MainFunction_Start_RoutineServices_DcmDspRoutine_RcPad: operation=RoutineServices_DcmDspRoutine_RcPad.Start
            OpServerCallDcm_MainFunction_ReadData_DataServices_DcmDspData_SvkBackup39: operation=DataServices_DcmDspData_SvkBackup39.ReadData
            OpServerCallDcm_MainFunction_ConditionCheckRead_DataServices_DcmDspData_SvkBackup39: operation=DataServices_DcmDspData_SvkBackup39.ConditionCheckRead
            OpServerCallDcm_MainFunction_ReadData_DataServices_DcmDspData_SvkBackup38: operation=DataServices_DcmDspData_SvkBackup38.ReadData
            OpServerCallDcm_MainFunction_ConditionCheckRead_DataServices_DcmDspData_SvkBackup38: operation=DataServices_DcmDspData_SvkBackup38.ConditionCheckRead
            OpServerCallDcm_MainFunction_ReadData_DataServices_DcmDspData_SvkBackup37: operation=DataServices_DcmDspData_SvkBackup37.ReadData
            OpServerCallDcm_MainFunction_ConditionCheckRead_DataServices_DcmDspData_SvkBackup37: operation=DataServices_DcmDspData_SvkBackup37.ConditionCheckRead
            OpServerCallDcm_MainFunction_ReadData_DataServices_DcmDspData_SvkBackup36: operation=DataServices_DcmDspData_SvkBackup36.ReadData
            OpServerCallDcm_MainFunction_ConditionCheckRead_DataServices_DcmDspData_SvkBackup36: operation=DataServices_DcmDspData_SvkBackup36.ConditionCheckRead
            OpServerCallDcm_MainFunction_ReadData_DataServices_DcmDspData_SvkBackup35: operation=DataServices_DcmDspData_SvkBackup35.ReadData
            OpServerCallDcm_MainFunction_ConditionCheckRead_DataServices_DcmDspData_SvkBackup35: operation=DataServices_DcmDspData_SvkBackup35.ConditionCheckRead
            OpServerCallDcm_MainFunction_ReadData_DataServices_DcmDspData_SvkBackup34: operation=DataServices_DcmDspData_SvkBackup34.ReadData
            OpServerCallDcm_MainFunction_ConditionCheckRead_DataServices_DcmDspData_SvkBackup34: operation=DataServices_DcmDspData_SvkBackup34.ConditionCheckRead
            OpServerCallDcm_MainFunction_ReadData_DataServices_DcmDspData_SvkBackup33: operation=DataServices_DcmDspData_SvkBackup33.ReadData
            OpServerCallDcm_MainFunction_ConditionCheckRead_DataServices_DcmDspData_SvkBackup33: operation=DataServices_DcmDspData_SvkBackup33.ConditionCheckRead
            OpServerCallDcm_MainFunction_ReadData_DataServices_DcmDspData_SvkBackup32: operation=DataServices_DcmDspData_SvkBackup32.ReadData
            OpServerCallDcm_MainFunction_ConditionCheckRead_DataServices_DcmDspData_SvkBackup32: operation=DataServices_DcmDspData_SvkBackup32.ConditionCheckRead
            OpServerCallDcm_MainFunction_ReadData_DataServices_DcmDspData_SvkBackup31: operation=DataServices_DcmDspData_SvkBackup31.ReadData
            OpServerCallDcm_MainFunction_ConditionCheckRead_DataServices_DcmDspData_SvkBackup31: operation=DataServices_DcmDspData_SvkBackup31.ConditionCheckRead
            OpServerCallDcm_MainFunction_ReadData_DataServices_DcmDspData_SvkBackup30: operation=DataServices_DcmDspData_SvkBackup30.ReadData
            OpServerCallDcm_MainFunction_ConditionCheckRead_DataServices_DcmDspData_SvkBackup30: operation=DataServices_DcmDspData_SvkBackup30.ConditionCheckRead
            OpServerCallDcm_MainFunction_ReadData_DataServices_DcmDspData_EthGetNumberOfPorts: operation=DataServices_DcmDspData_EthGetNumberOfPorts.ReadData
            OpServerCallDcm_MainFunction_ConditionCheckRead_DataServices_DcmDspData_EthGetNumberOfPorts: operation=DataServices_DcmDspData_EthGetNumberOfPorts.ConditionCheckRead
            OpServerCallDcm_MainFunction_ReadData_DataServices_DcmDspData_SvkBackup28: operation=DataServices_DcmDspData_SvkBackup28.ReadData
            OpServerCallDcm_MainFunction_ConditionCheckRead_DataServices_DcmDspData_SvkBackup28: operation=DataServices_DcmDspData_SvkBackup28.ConditionCheckRead
            OpServerCallDcm_MainFunction_ReadData_DataServices_DcmDspData_SvkBackup27: operation=DataServices_DcmDspData_SvkBackup27.ReadData
            OpServerCallDcm_MainFunction_ConditionCheckRead_DataServices_DcmDspData_SvkBackup27: operation=DataServices_DcmDspData_SvkBackup27.ConditionCheckRead
            OpServerCallDcm_MainFunction_ReadData_DataServices_DcmDspData_SvkBackup26: operation=DataServices_DcmDspData_SvkBackup26.ReadData
            OpServerCallDcm_MainFunction_ConditionCheckRead_DataServices_DcmDspData_SvkBackup26: operation=DataServices_DcmDspData_SvkBackup26.ConditionCheckRead
            OpServerCallDcm_MainFunction_ReadData_DataServices_DcmDspData_SvkBackup25: operation=DataServices_DcmDspData_SvkBackup25.ReadData
            OpServerCallDcm_MainFunction_ConditionCheckRead_DataServices_DcmDspData_SvkBackup25: operation=DataServices_DcmDspData_SvkBackup25.ConditionCheckRead
            OpServerCallDcm_MainFunction_ReadData_DataServices_DcmDspData_SvkBackup24: operation=DataServices_DcmDspData_SvkBackup24.ReadData
            OpServerCallDcm_MainFunction_ConditionCheckRead_DataServices_DcmDspData_SvkBackup24: operation=DataServices_DcmDspData_SvkBackup24.ConditionCheckRead
            OpServerCallDcm_MainFunction_ReadData_DataServices_DcmDspData_SvkBackup23: operation=DataServices_DcmDspData_SvkBackup23.ReadData
            OpServerCallDcm_MainFunction_ConditionCheckRead_DataServices_DcmDspData_SvkBackup23: operation=DataServices_DcmDspData_SvkBackup23.ConditionCheckRead
            OpServerCallDcm_MainFunction_ReadData_DataServices_DcmDspData_SvkBackup22: operation=DataServices_DcmDspData_SvkBackup22.ReadData
            OpServerCallDcm_MainFunction_ConditionCheckRead_DataServices_DcmDspData_SvkBackup22: operation=DataServices_DcmDspData_SvkBackup22.ConditionCheckRead
            OpServerCallDcm_MainFunction_ReadData_DataServices_DcmDspData_SvkBackup21: operation=DataServices_DcmDspData_SvkBackup21.ReadData
            OpServerCallDcm_MainFunction_ConditionCheckRead_DataServices_DcmDspData_SvkBackup21: operation=DataServices_DcmDspData_SvkBackup21.ConditionCheckRead
            OpServerCallDcm_MainFunction_ReadData_DataServices_DcmDspData_SvkBackup20: operation=DataServices_DcmDspData_SvkBackup20.ReadData
            OpServerCallDcm_MainFunction_ConditionCheckRead_DataServices_DcmDspData_SvkBackup20: operation=DataServices_DcmDspData_SvkBackup20.ConditionCheckRead
            OpServerCallDcm_MainFunction_ReadData_DataServices_DcmDspData_SvkBackup29: operation=DataServices_DcmDspData_SvkBackup29.ReadData
            OpServerCallDcm_MainFunction_ConditionCheckRead_DataServices_DcmDspData_SvkBackup29: operation=DataServices_DcmDspData_SvkBackup29.ConditionCheckRead
            OpServerCallDcm_MainFunction_ReadData_DataServices_DcmDspData_ListManipulationSecurityArtifact: operation=DataServices_DcmDspData_ListManipulationSecurityArtifact.ReadData
            OpServerCallDcm_MainFunction_ConditionCheckRead_DataServices_DcmDspData_ListManipulationSecurityArtifact: operation=DataServices_DcmDspData_ListManipulationSecurityArtifact.ConditionCheckRead
            OpServerCallDcm_MainFunction_ReadData_DataServices_DcmDspData_SvkBackup17: operation=DataServices_DcmDspData_SvkBackup17.ReadData
            OpServerCallDcm_MainFunction_ConditionCheckRead_DataServices_DcmDspData_SvkBackup17: operation=DataServices_DcmDspData_SvkBackup17.ConditionCheckRead
            OpServerCallDcm_MainFunction_ReadData_DataServices_DcmDspData_SvkBackup16: operation=DataServices_DcmDspData_SvkBackup16.ReadData
            OpServerCallDcm_MainFunction_ConditionCheckRead_DataServices_DcmDspData_SvkBackup16: operation=DataServices_DcmDspData_SvkBackup16.ConditionCheckRead
            OpServerCallDcm_MainFunction_ReadData_DataServices_DcmDspData_SvkBackup15: operation=DataServices_DcmDspData_SvkBackup15.ReadData
            OpServerCallDcm_MainFunction_ConditionCheckRead_DataServices_DcmDspData_SvkBackup15: operation=DataServices_DcmDspData_SvkBackup15.ConditionCheckRead
            OpServerCallDcm_MainFunction_ReadData_DataServices_DcmDspData_SvkBackup14: operation=DataServices_DcmDspData_SvkBackup14.ReadData
            OpServerCallDcm_MainFunction_ConditionCheckRead_DataServices_DcmDspData_SvkBackup14: operation=DataServices_DcmDspData_SvkBackup14.ConditionCheckRead
            OpServerCallDcm_MainFunction_ReadData_DataServices_DcmDspData_SvkBackup13: operation=DataServices_DcmDspData_SvkBackup13.ReadData
            OpServerCallDcm_MainFunction_ConditionCheckRead_DataServices_DcmDspData_SvkBackup13: operation=DataServices_DcmDspData_SvkBackup13.ConditionCheckRead
            OpServerCallDcm_MainFunction_ReadData_DataServices_DcmDspData_SvkBackup12: operation=DataServices_DcmDspData_SvkBackup12.ReadData
            OpServerCallDcm_MainFunction_ConditionCheckRead_DataServices_DcmDspData_SvkBackup12: operation=DataServices_DcmDspData_SvkBackup12.ConditionCheckRead
            OpServerCallDcm_MainFunction_ReadData_DataServices_DcmDspData_SvkBackup11: operation=DataServices_DcmDspData_SvkBackup11.ReadData
            OpServerCallDcm_MainFunction_ConditionCheckRead_DataServices_DcmDspData_SvkBackup11: operation=DataServices_DcmDspData_SvkBackup11.ConditionCheckRead
            OpServerCallDcm_MainFunction_ReadData_DataServices_DcmDspData_SvkBackup10: operation=DataServices_DcmDspData_SvkBackup10.ReadData
            OpServerCallDcm_MainFunction_ConditionCheckRead_DataServices_DcmDspData_SvkBackup10: operation=DataServices_DcmDspData_SvkBackup10.ConditionCheckRead
            OpServerCallDcm_MainFunction_ReadData_DataServices_DcmDspData_SvkBackup19: operation=DataServices_DcmDspData_SvkBackup19.ReadData
            OpServerCallDcm_MainFunction_ConditionCheckRead_DataServices_DcmDspData_SvkBackup19: operation=DataServices_DcmDspData_SvkBackup19.ConditionCheckRead
            OpServerCallDcm_MainFunction_ReadData_DataServices_DcmDspData_SvkBackup18: operation=DataServices_DcmDspData_SvkBackup18.ReadData
            OpServerCallDcm_MainFunction_ConditionCheckRead_DataServices_DcmDspData_SvkBackup18: operation=DataServices_DcmDspData_SvkBackup18.ConditionCheckRead
            OpServerCallDcm_MainFunction_ReadData_DataServices_DcmDspData_SvkBackup06: operation=DataServices_DcmDspData_SvkBackup06.ReadData
            OpServerCallDcm_MainFunction_ConditionCheckRead_DataServices_DcmDspData_SvkBackup06: operation=DataServices_DcmDspData_SvkBackup06.ConditionCheckRead
            OpServerCallDcm_MainFunction_ReadData_DataServices_DcmDspData_SvkBackup05: operation=DataServices_DcmDspData_SvkBackup05.ReadData
            OpServerCallDcm_MainFunction_ConditionCheckRead_DataServices_DcmDspData_SvkBackup05: operation=DataServices_DcmDspData_SvkBackup05.ConditionCheckRead
            OpServerCallDcm_MainFunction_ReadData_DataServices_DcmDspData_SvkBackup04: operation=DataServices_DcmDspData_SvkBackup04.ReadData
            OpServerCallDcm_MainFunction_ConditionCheckRead_DataServices_DcmDspData_SvkBackup04: operation=DataServices_DcmDspData_SvkBackup04.ConditionCheckRead
            OpServerCallDcm_MainFunction_ReadData_DataServices_DcmDspData_SvkBackup03: operation=DataServices_DcmDspData_SvkBackup03.ReadData
            OpServerCallDcm_MainFunction_ConditionCheckRead_DataServices_DcmDspData_SvkBackup03: operation=DataServices_DcmDspData_SvkBackup03.ConditionCheckRead
            OpServerCallDcm_MainFunction_ReadData_DataServices_DcmDspData_SvkBackup02: operation=DataServices_DcmDspData_SvkBackup02.ReadData
            OpServerCallDcm_MainFunction_ConditionCheckRead_DataServices_DcmDspData_SvkBackup02: operation=DataServices_DcmDspData_SvkBackup02.ConditionCheckRead
            OpServerCallDcm_MainFunction_ReadData_DataServices_DcmDspData_SvkBackup01: operation=DataServices_DcmDspData_SvkBackup01.ReadData
            OpServerCallDcm_MainFunction_ConditionCheckRead_DataServices_DcmDspData_SvkBackup01: operation=DataServices_DcmDspData_SvkBackup01.ConditionCheckRead
            OpServerCallDcm_MainFunction_ReadData_DataServices_DcmDspData_StatusSystime: operation=DataServices_DcmDspData_StatusSystime.ReadData
            OpServerCallDcm_MainFunction_ConditionCheckRead_DataServices_DcmDspData_StatusSystime: operation=DataServices_DcmDspData_StatusSystime.ConditionCheckRead
            OpServerCallDcm_MainFunction_ReadData_DataServices_DcmDspData_SvkBackup09: operation=DataServices_DcmDspData_SvkBackup09.ReadData
            OpServerCallDcm_MainFunction_ConditionCheckRead_DataServices_DcmDspData_SvkBackup09: operation=DataServices_DcmDspData_SvkBackup09.ConditionCheckRead
            OpServerCallDcm_MainFunction_ReadData_DataServices_DcmDspData_SvkBackup08: operation=DataServices_DcmDspData_SvkBackup08.ReadData
            OpServerCallDcm_MainFunction_ConditionCheckRead_DataServices_DcmDspData_SvkBackup08: operation=DataServices_DcmDspData_SvkBackup08.ConditionCheckRead
            OpServerCallDcm_MainFunction_ReadData_DataServices_DcmDspData_SvkBackup07: operation=DataServices_DcmDspData_SvkBackup07.ReadData
            OpServerCallDcm_MainFunction_ConditionCheckRead_DataServices_DcmDspData_SvkBackup07: operation=DataServices_DcmDspData_SvkBackup07.ConditionCheckRead
            OpServerCallDcm_MainFunction_ReadData_DataServices_DcmDspData_HddDownloadTimeToCompletion: operation=DataServices_DcmDspData_HddDownloadTimeToCompletion.ReadData
            OpServerCallDcm_MainFunction_ConditionCheckRead_DataServices_DcmDspData_HddDownloadTimeToCompletion: operation=DataServices_DcmDspData_HddDownloadTimeToCompletion.ConditionCheckRead
            OpServerCallDcm_MainFunction_ReadData_DataServices_DcmDspData_StatusDmFssMaster: operation=DataServices_DcmDspData_StatusDmFssMaster.ReadData
            OpServerCallDcm_MainFunction_ConditionCheckRead_DataServices_DcmDspData_StatusDmFssMaster: operation=DataServices_DcmDspData_StatusDmFssMaster.ConditionCheckRead
            OpServerCallDcm_MainFunction_ReadData_DataServices_DcmDspData_HddDownloadStatus: operation=DataServices_DcmDspData_HddDownloadStatus.ReadData
            OpServerCallDcm_MainFunction_ConditionCheckRead_DataServices_DcmDspData_HddDownloadStatus: operation=DataServices_DcmDspData_HddDownloadStatus.ConditionCheckRead
            OpServerCallDcm_MainFunction_ReadData_DataServices_DcmDspData_SvkAktuell: operation=DataServices_DcmDspData_SvkAktuell.ReadData
            OpServerCallDcm_MainFunction_ReadDataLength_DataServices_DcmDspData_SvkAktuell: operation=DataServices_DcmDspData_SvkAktuell.ReadDataLength
            OpServerCallDcm_MainFunction_ConditionCheckRead_DataServices_DcmDspData_SvkAktuell: operation=DataServices_DcmDspData_SvkAktuell.ConditionCheckRead
            OpServerCallDcm_MainFunction_ReadData_DataServices_DcmDspData_Readhwmodificationindex: operation=DataServices_DcmDspData_Readhwmodificationindex.ReadData
            OpServerCallDcm_MainFunction_ReadData_DataServices_DcmDspData_SensorenAnzahlLesen: operation=DataServices_DcmDspData_SensorenAnzahlLesen.ReadData
            OpServerCallDcm_MainFunction_ConditionCheckRead_DataServices_DcmDspData_SensorenAnzahlLesen: operation=DataServices_DcmDspData_SensorenAnzahlLesen.ConditionCheckRead
            OpServerCallDcm_MainFunction_ReadData_DataServices_DcmDspData_IndivDataTable: operation=DataServices_DcmDspData_IndivDataTable.ReadData
            OpServerCallDcm_MainFunction_ReadData_DataServices_DcmDspData_DmDtcAktiveMeldung: operation=DataServices_DcmDspData_DmDtcAktiveMeldung.ReadData
            OpServerCallDcm_MainFunction_ReadDataLength_DataServices_DcmDspData_DmDtcAktiveMeldung: operation=DataServices_DcmDspData_DmDtcAktiveMeldung.ReadDataLength
            OpServerCallDcm_MainFunction_ConditionCheckRead_DataServices_DcmDspData_DmDtcAktiveMeldung: operation=DataServices_DcmDspData_DmDtcAktiveMeldung.ConditionCheckRead
            OpServerCallDcm_MainFunction_ReadData_DataServices_DcmDspData_SwfkDeleteSupported: operation=DataServices_DcmDspData_SwfkDeleteSupported.ReadData
            OpServerCallDcm_MainFunction_ReadData_DataServices_DcmDspData_FlashTimingParameter: operation=DataServices_DcmDspData_FlashTimingParameter.ReadData
            OpServerCallDcm_MainFunction_ReadData_DataServices_DcmDspData_ListManipulationApplicationData: operation=DataServices_DcmDspData_ListManipulationApplicationData.ReadData
            OpServerCallDcm_MainFunction_ConditionCheckRead_DataServices_DcmDspData_ListManipulationApplicationData: operation=DataServices_DcmDspData_ListManipulationApplicationData.ConditionCheckRead
            OpServerCallDcm_MainFunction_ReadData_DataServices_DcmDspData_Vin: operation=DataServices_DcmDspData_Vin.ReadData
            OpServerCallDcm_MainFunction_ConditionCheckRead_DataServices_DcmDspData_Vin: operation=DataServices_DcmDspData_Vin.ConditionCheckRead
            OpServerCallDcm_MainFunction_ReadData_DataServices_DcmDspData_EnergySavingState: operation=DataServices_DcmDspData_EnergySavingState.ReadData
            OpServerCallDcm_MainFunction_ConditionCheckRead_DataServices_DcmDspData_EnergySavingState: operation=DataServices_DcmDspData_EnergySavingState.ConditionCheckRead
            OpServerCallDcm_MainFunction_ReadData_DataServices_DcmDspData_ReadActiveSessionState: operation=DataServices_DcmDspData_ReadActiveSessionState.ReadData
            OpServerCallDcm_MainFunction_ConditionCheckRead_DataServices_DcmDspData_ReadActiveSessionState: operation=DataServices_DcmDspData_ReadActiveSessionState.ConditionCheckRead
            OpServerCallDcm_MainFunction_ReadData_DataServices_DcmDspData_EthPhyLinkState: operation=DataServices_DcmDspData_EthPhyLinkState.ReadData
            OpServerCallDcm_MainFunction_ConditionCheckRead_DataServices_DcmDspData_EthPhyLinkState: operation=DataServices_DcmDspData_EthPhyLinkState.ConditionCheckRead
            OpServerCallDcm_MainFunction_ReadData_DataServices_DcmDspData_EthSignalQuality: operation=DataServices_DcmDspData_EthSignalQuality.ReadData
            OpServerCallDcm_MainFunction_ConditionCheckRead_DataServices_DcmDspData_EthSignalQuality: operation=DataServices_DcmDspData_EthSignalQuality.ConditionCheckRead
            OpServerCallDcm_MainFunction_ReadData_DataServices_DcmDspData_ListManipulationSw: operation=DataServices_DcmDspData_ListManipulationSw.ReadData
            OpServerCallDcm_MainFunction_ConditionCheckRead_DataServices_DcmDspData_ListManipulationSw: operation=DataServices_DcmDspData_ListManipulationSw.ConditionCheckRead
            OpServerCallDcm_MainFunction_ReadData_DataServices_DcmDspData_Herstelldatum: operation=DataServices_DcmDspData_Herstelldatum.ReadData
            OpServerCallDcm_MainFunction_ReadData_DataServices_DcmDspData_Sekundaererfehlerspeicher: operation=DataServices_DcmDspData_Sekundaererfehlerspeicher.ReadData
            OpServerCallDcm_MainFunction_ConditionCheckRead_DataServices_DcmDspData_Sekundaererfehlerspeicher: operation=DataServices_DcmDspData_Sekundaererfehlerspeicher.ConditionCheckRead
            OpServerCallDcm_MainFunction_ReadData_DataServices_DcmDspData_SystemSupplierIdentifier: operation=DataServices_DcmDspData_SystemSupplierIdentifier.ReadData
            OpServerCallDcm_MainFunction_ConditionCheckRead_DataServices_DcmDspData_SystemSupplierIdentifier: operation=DataServices_DcmDspData_SystemSupplierIdentifier.ConditionCheckRead
            OpServerCallDcm_MainFunction_ReadData_DataServices_DcmDspData_MileKmEeprom: operation=DataServices_DcmDspData_MileKmEeprom.ReadData
            OpServerCallDcm_MainFunction_ConditionCheckRead_DataServices_DcmDspData_MileKmEeprom: operation=DataServices_DcmDspData_MileKmEeprom.ConditionCheckRead
            OpServerCallDcm_MainFunction_ReadData_DataServices_DcmDspData_ListManipulationGeneral: operation=DataServices_DcmDspData_ListManipulationGeneral.ReadData
            OpServerCallDcm_MainFunction_ConditionCheckRead_DataServices_DcmDspData_ListManipulationGeneral: operation=DataServices_DcmDspData_ListManipulationGeneral.ConditionCheckRead
            OpServerCallDcm_MainFunction_ReadData_DataServices_DcmDspData_SvkWerk: operation=DataServices_DcmDspData_SvkWerk.ReadData
            OpServerCallDcm_MainFunction_ConditionCheckRead_DataServices_DcmDspData_SvkWerk: operation=DataServices_DcmDspData_SvkWerk.ConditionCheckRead
            OpServerCallDcm_MainFunction_ReadData_DataServices_DcmDspData_ProgrammingCounterMaxValue: operation=DataServices_DcmDspData_ProgrammingCounterMaxValue.ReadData
            OpServerCallDcm_MainFunction_ReadData_DataServices_DcmDspData_EcuSerialNumber: operation=DataServices_DcmDspData_EcuSerialNumber.ReadData
            OpServerCallDcm_MainFunction_ReadData_DataServices_DcmDspData_SgbdIdx: operation=DataServices_DcmDspData_SgbdIdx.ReadData
            OpServerCallDcm_MainFunction_ReadData_DataServices_DcmDspData_ZgwZertifikat: operation=DataServices_DcmDspData_ZgwZertifikat.ReadData
            OpServerCallDcm_MainFunction_ConditionCheckRead_DataServices_DcmDspData_ZgwZertifikat: operation=DataServices_DcmDspData_ZgwZertifikat.ConditionCheckRead
            OpServerCallDcm_MainFunction_ReadData_DataServices_DcmDspData_ListManipulationSecureBoot: operation=DataServices_DcmDspData_ListManipulationSecureBoot.ReadData
            OpServerCallDcm_MainFunction_ConditionCheckRead_DataServices_DcmDspData_ListManipulationSecureBoot: operation=DataServices_DcmDspData_ListManipulationSecureBoot.ConditionCheckRead
            OpServerCallDcm_MainFunction_ReadData_DataServices_DcmDspData_DmIsDtcActiveResponse: operation=DataServices_DcmDspData_DmIsDtcActiveResponse.ReadData
            OpServerCallDcm_MainFunction_ReadDataLength_DataServices_DcmDspData_DmIsDtcActiveResponse: operation=DataServices_DcmDspData_DmIsDtcActiveResponse.ReadDataLength
            OpServerCallDcm_MainFunction_ConditionCheckRead_DataServices_DcmDspData_DmIsDtcActiveResponse: operation=DataServices_DcmDspData_DmIsDtcActiveResponse.ConditionCheckRead
            OpServerCallDcm_MainFunction_ReadData_DataServices_DcmDspData_ExtendedEnergySavingState: operation=DataServices_DcmDspData_ExtendedEnergySavingState.ReadData
            OpServerCallDcm_MainFunction_ConditionCheckRead_DataServices_DcmDspData_ExtendedEnergySavingState: operation=DataServices_DcmDspData_ExtendedEnergySavingState.ConditionCheckRead
            OpServerCallDcm_MainFunction_ReadData_DataServices_DcmDspData_SvkBackup61: operation=DataServices_DcmDspData_SvkBackup61.ReadData
            OpServerCallDcm_MainFunction_ConditionCheckRead_DataServices_DcmDspData_SvkBackup61: operation=DataServices_DcmDspData_SvkBackup61.ConditionCheckRead
            OpServerCallDcm_MainFunction_ReadData_DataServices_DcmDspData_PiaProfile0: operation=DataServices_DcmDspData_PiaProfile0.ReadData
            OpServerCallDcm_MainFunction_ReadDataLength_DataServices_DcmDspData_PiaProfile0: operation=DataServices_DcmDspData_PiaProfile0.ReadDataLength
            OpServerCallDcm_MainFunction_ConditionCheckRead_DataServices_DcmDspData_PiaProfile0: operation=DataServices_DcmDspData_PiaProfile0.ConditionCheckRead
            OpServerCallDcm_MainFunction_WriteData_DataServices_DcmDspData_PiaProfile0: operation=DataServices_DcmDspData_PiaProfile0.WriteData
            OpServerCallDcm_MainFunction_ReadData_DataServices_DcmDspData_SvkBackup60: operation=DataServices_DcmDspData_SvkBackup60.ReadData
            OpServerCallDcm_MainFunction_ConditionCheckRead_DataServices_DcmDspData_SvkBackup60: operation=DataServices_DcmDspData_SvkBackup60.ConditionCheckRead
            OpServerCallDcm_MainFunction_ReadData_DataServices_DcmDspData_PiaProfile1: operation=DataServices_DcmDspData_PiaProfile1.ReadData
            OpServerCallDcm_MainFunction_ReadDataLength_DataServices_DcmDspData_PiaProfile1: operation=DataServices_DcmDspData_PiaProfile1.ReadDataLength
            OpServerCallDcm_MainFunction_ConditionCheckRead_DataServices_DcmDspData_PiaProfile1: operation=DataServices_DcmDspData_PiaProfile1.ConditionCheckRead
            OpServerCallDcm_MainFunction_WriteData_DataServices_DcmDspData_PiaProfile1: operation=DataServices_DcmDspData_PiaProfile1.WriteData
            OpServerCallDcm_MainFunction_ReadData_DataServices_DcmDspData_PiaProfile2: operation=DataServices_DcmDspData_PiaProfile2.ReadData
            OpServerCallDcm_MainFunction_ReadDataLength_DataServices_DcmDspData_PiaProfile2: operation=DataServices_DcmDspData_PiaProfile2.ReadDataLength
            OpServerCallDcm_MainFunction_ConditionCheckRead_DataServices_DcmDspData_PiaProfile2: operation=DataServices_DcmDspData_PiaProfile2.ConditionCheckRead
            OpServerCallDcm_MainFunction_WriteData_DataServices_DcmDspData_PiaProfile2: operation=DataServices_DcmDspData_PiaProfile2.WriteData
            OpServerCallDcm_MainFunction_ReadData_DataServices_DcmDspData_SvkSysSupplier: operation=DataServices_DcmDspData_SvkSysSupplier.ReadData
            OpServerCallDcm_MainFunction_ConditionCheckRead_DataServices_DcmDspData_SvkSysSupplier: operation=DataServices_DcmDspData_SvkSysSupplier.ConditionCheckRead
            OpServerCallDcm_MainFunction_ReadData_DataServices_DcmDspData_PiaProfileA: operation=DataServices_DcmDspData_PiaProfileA.ReadData
            OpServerCallDcm_MainFunction_ReadDataLength_DataServices_DcmDspData_PiaProfileA: operation=DataServices_DcmDspData_PiaProfileA.ReadDataLength
            OpServerCallDcm_MainFunction_ConditionCheckRead_DataServices_DcmDspData_PiaProfileA: operation=DataServices_DcmDspData_PiaProfileA.ConditionCheckRead
            OpServerCallDcm_MainFunction_WriteData_DataServices_DcmDspData_PiaProfileA: operation=DataServices_DcmDspData_PiaProfileA.WriteData
            OpServerCallDcm_MainFunction_ReadData_DataServices_DcmDspData_SvkBackup59: operation=DataServices_DcmDspData_SvkBackup59.ReadData
            OpServerCallDcm_MainFunction_ConditionCheckRead_DataServices_DcmDspData_SvkBackup59: operation=DataServices_DcmDspData_SvkBackup59.ConditionCheckRead
            OpServerCallDcm_MainFunction_ReadData_DataServices_DcmDspData_SvkBackup58: operation=DataServices_DcmDspData_SvkBackup58.ReadData
            OpServerCallDcm_MainFunction_ConditionCheckRead_DataServices_DcmDspData_SvkBackup58: operation=DataServices_DcmDspData_SvkBackup58.ConditionCheckRead
            OpServerCallDcm_MainFunction_ReadData_DataServices_DcmDspData_SvkBackup57: operation=DataServices_DcmDspData_SvkBackup57.ReadData
            OpServerCallDcm_MainFunction_ConditionCheckRead_DataServices_DcmDspData_SvkBackup57: operation=DataServices_DcmDspData_SvkBackup57.ConditionCheckRead
            OpServerCallDcm_MainFunction_ReadData_DataServices_DcmDspData_SvkBackup56: operation=DataServices_DcmDspData_SvkBackup56.ReadData
            OpServerCallDcm_MainFunction_ConditionCheckRead_DataServices_DcmDspData_SvkBackup56: operation=DataServices_DcmDspData_SvkBackup56.ConditionCheckRead
            OpServerCallDcm_MainFunction_ReadData_DataServices_DcmDspData_SvkBackup55: operation=DataServices_DcmDspData_SvkBackup55.ReadData
            OpServerCallDcm_MainFunction_ConditionCheckRead_DataServices_DcmDspData_SvkBackup55: operation=DataServices_DcmDspData_SvkBackup55.ConditionCheckRead
            OpServerCallDcm_MainFunction_ReadData_DataServices_DcmDspData_SvkBackup54: operation=DataServices_DcmDspData_SvkBackup54.ReadData
            OpServerCallDcm_MainFunction_ConditionCheckRead_DataServices_DcmDspData_SvkBackup54: operation=DataServices_DcmDspData_SvkBackup54.ConditionCheckRead
            OpServerCallDcm_MainFunction_ReadData_DataServices_DcmDspData_SvkBackup53: operation=DataServices_DcmDspData_SvkBackup53.ReadData
            OpServerCallDcm_MainFunction_ConditionCheckRead_DataServices_DcmDspData_SvkBackup53: operation=DataServices_DcmDspData_SvkBackup53.ConditionCheckRead
            OpServerCallDcm_MainFunction_ReadData_DataServices_DcmDspData_SvkBackup52: operation=DataServices_DcmDspData_SvkBackup52.ReadData
            OpServerCallDcm_MainFunction_ConditionCheckRead_DataServices_DcmDspData_SvkBackup52: operation=DataServices_DcmDspData_SvkBackup52.ConditionCheckRead
            OpServerCallDcm_MainFunction_ReadData_DataServices_DcmDspData_SvkBackup51: operation=DataServices_DcmDspData_SvkBackup51.ReadData
            OpServerCallDcm_MainFunction_ConditionCheckRead_DataServices_DcmDspData_SvkBackup51: operation=DataServices_DcmDspData_SvkBackup51.ConditionCheckRead
            OpServerCallDcm_MainFunction_ReadData_DataServices_DcmDspData_SvkBackup50: operation=DataServices_DcmDspData_SvkBackup50.ReadData
            OpServerCallDcm_MainFunction_ConditionCheckRead_DataServices_DcmDspData_SvkBackup50: operation=DataServices_DcmDspData_SvkBackup50.ConditionCheckRead
            OpServerCallDcm_MainFunction_ReadData_DataServices_DcmDspData_ProgrammingCounter: operation=DataServices_DcmDspData_ProgrammingCounter.ReadData
            OpServerCallDcm_MainFunction_ReadData_DataServices_DcmDspData_Systemzeit: operation=DataServices_DcmDspData_Systemzeit.ReadData
            OpServerCallDcm_MainFunction_ReadData_DataServices_DcmDspData_SvkBackup49: operation=DataServices_DcmDspData_SvkBackup49.ReadData
            OpServerCallDcm_MainFunction_ConditionCheckRead_DataServices_DcmDspData_SvkBackup49: operation=DataServices_DcmDspData_SvkBackup49.ConditionCheckRead
            OpServerCallDcm_MainFunction_ReadData_DataServices_DcmDspData_SvkBackup48: operation=DataServices_DcmDspData_SvkBackup48.ReadData
            OpServerCallDcm_MainFunction_ConditionCheckRead_DataServices_DcmDspData_SvkBackup48: operation=DataServices_DcmDspData_SvkBackup48.ConditionCheckRead
            OpServerCallDcm_MainFunction_ReadData_DataServices_DcmDspData_SvkBackup47: operation=DataServices_DcmDspData_SvkBackup47.ReadData
            OpServerCallDcm_MainFunction_ConditionCheckRead_DataServices_DcmDspData_SvkBackup47: operation=DataServices_DcmDspData_SvkBackup47.ConditionCheckRead
            OpServerCallDcm_MainFunction_ReadData_DataServices_DcmDspData_SvkBackup46: operation=DataServices_DcmDspData_SvkBackup46.ReadData
            OpServerCallDcm_MainFunction_ConditionCheckRead_DataServices_DcmDspData_SvkBackup46: operation=DataServices_DcmDspData_SvkBackup46.ConditionCheckRead
            OpServerCallDcm_MainFunction_ReadData_DataServices_DcmDspData_SvkBackup45: operation=DataServices_DcmDspData_SvkBackup45.ReadData
            OpServerCallDcm_MainFunction_ConditionCheckRead_DataServices_DcmDspData_SvkBackup45: operation=DataServices_DcmDspData_SvkBackup45.ConditionCheckRead
            OpServerCallDcm_MainFunction_ReadData_DataServices_DcmDspData_SvkBackup44: operation=DataServices_DcmDspData_SvkBackup44.ReadData
            OpServerCallDcm_MainFunction_ConditionCheckRead_DataServices_DcmDspData_SvkBackup44: operation=DataServices_DcmDspData_SvkBackup44.ConditionCheckRead
            OpServerCallDcm_MainFunction_ReadData_DataServices_DcmDspData_SvkBackup43: operation=DataServices_DcmDspData_SvkBackup43.ReadData
            OpServerCallDcm_MainFunction_ConditionCheckRead_DataServices_DcmDspData_SvkBackup43: operation=DataServices_DcmDspData_SvkBackup43.ConditionCheckRead
            OpServerCallDcm_MainFunction_ReadData_DataServices_DcmDspData_SvkBackup42: operation=DataServices_DcmDspData_SvkBackup42.ReadData
            OpServerCallDcm_MainFunction_ConditionCheckRead_DataServices_DcmDspData_SvkBackup42: operation=DataServices_DcmDspData_SvkBackup42.ConditionCheckRead
            OpServerCallDcm_MainFunction_ReadData_DataServices_DcmDspData_SvkBackup41: operation=DataServices_DcmDspData_SvkBackup41.ReadData
            OpServerCallDcm_MainFunction_ConditionCheckRead_DataServices_DcmDspData_SvkBackup41: operation=DataServices_DcmDspData_SvkBackup41.ConditionCheckRead
            OpServerCallDcm_MainFunction_ReadData_DataServices_DcmDspData_SvkBackup40: operation=DataServices_DcmDspData_SvkBackup40.ReadData
            OpServerCallDcm_MainFunction_ConditionCheckRead_DataServices_DcmDspData_SvkBackup40: operation=DataServices_DcmDspData_SvkBackup40.ConditionCheckRead
            OpServerCallDcm_MainFunction_ReadDidData_DataServices_DIDRange_DcmDspDidRange_Coding: operation=DataServices_DIDRange_DcmDspDidRange_Coding.ReadDidData
            OpServerCallDcm_MainFunction_WriteDidData_DataServices_DIDRange_DcmDspDidRange_Coding: operation=DataServices_DIDRange_DcmDspDidRange_Coding.WriteDidData
            OpServerCallDcm_MainFunction_IsDidAvailable_DataServices_DIDRange_DcmDspDidRange_Coding: operation=DataServices_DIDRange_DcmDspDidRange_Coding.IsDidAvailable
            OpServerCallDcm_MainFunction_ReadData_DataServices_Data_DcmDspDid_SensorLesen_1: operation=DataServices_Data_DcmDspDid_SensorLesen_1.ReadData
            OpServerCallDcm_MainFunction_ConditionCheckRead_DataServices_Data_DcmDspDid_SensorLesen_1: operation=DataServices_Data_DcmDspDid_SensorLesen_1.ConditionCheckRead
            OpServerCallDcm_MainFunction_ReadData_DataServices_Data_DcmDspDid_SensorLesen_2: operation=DataServices_Data_DcmDspDid_SensorLesen_2.ReadData
            OpServerCallDcm_MainFunction_ConditionCheckRead_DataServices_Data_DcmDspDid_SensorLesen_2: operation=DataServices_Data_DcmDspDid_SensorLesen_2.ConditionCheckRead
            OpServerCallDcm_MainFunction_ReadData_DataServices_Data_DcmDspDid_SensorLesen_3: operation=DataServices_Data_DcmDspDid_SensorLesen_3.ReadData
            OpServerCallDcm_MainFunction_ConditionCheckRead_DataServices_Data_DcmDspDid_SensorLesen_3: operation=DataServices_Data_DcmDspDid_SensorLesen_3.ConditionCheckRead
        GetActiveProtocol: can-be-invoked-concurrently=true, symbol=Dcm_GetActiveProtocol
        GetSesCtrlType: can-be-invoked-concurrently=true, symbol=Dcm_GetSesCtrlType
        ResetToDefaultSession: can-be-invoked-concurrently=true, symbol=Dcm_ResetToDefaultSession
        GetSecurityLevel: can-be-invoked-concurrently=true, symbol=Dcm_GetSecurityLevel
        SetActiveDiagnostic: can-be-invoked-concurrently=true, symbol=Dcm_SetActiveDiagnostic
        GetRequestKind: can-be-invoked-concurrently=true, symbol=Dcm_GetRequestKind
        TriggerOnEvent: can-be-invoked-concurrently=true, symbol=Dcm_TriggerOnEvent
  swc implementation DcmImplementation: programming-language=C, behavior=DcmInternalBehavior
